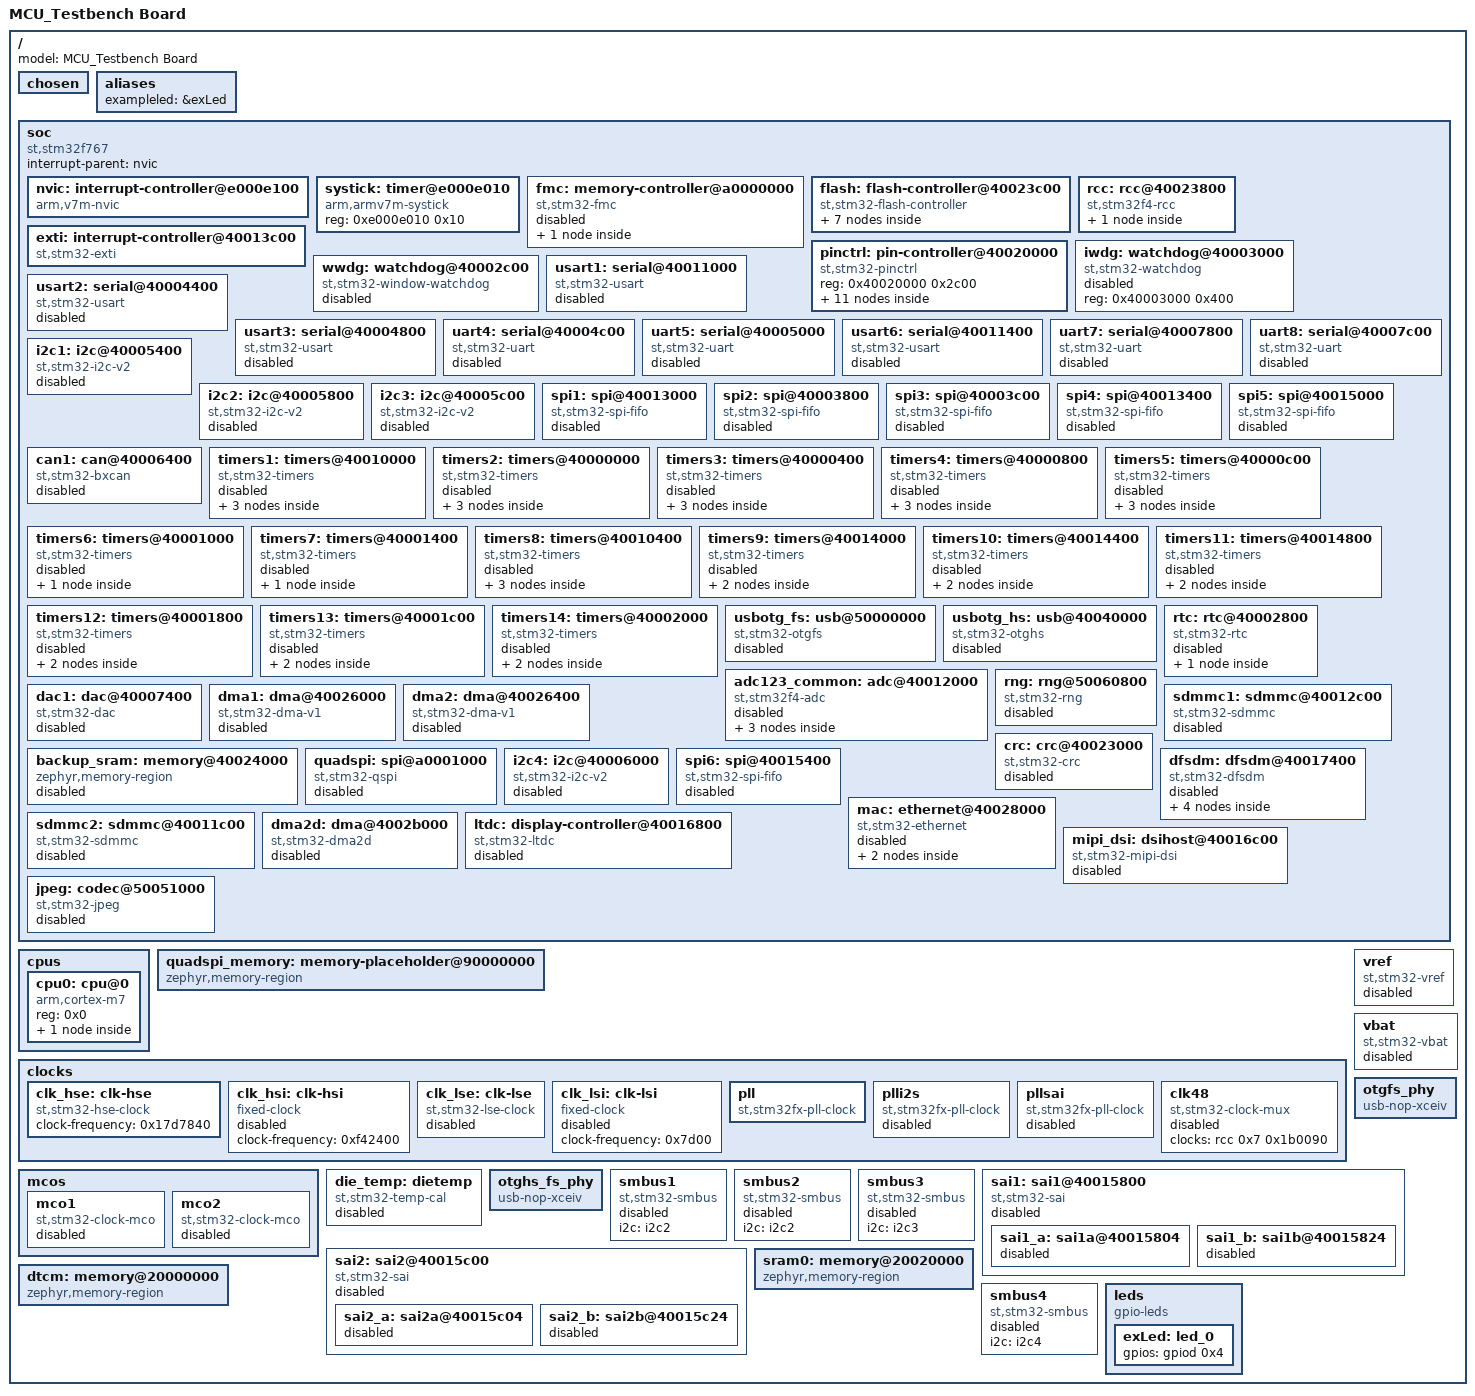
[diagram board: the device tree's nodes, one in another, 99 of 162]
/dts-v1/;

/* node '/' defined in zephyr\dts\common\skeleton.dtsi:9 */
/ {
	#address-cells = < 0x1 >;      /* in zephyr\dts\common\skeleton.dtsi:10 */
	#size-cells = < 0x1 >;         /* in zephyr\dts\common\skeleton.dtsi:11 */
	model = "MCU_Testbench Board"; /* in MCU_Testbench\boards\arm\MCU_Testbench\MCU_Testbench.dts:6 */

	/* node '/chosen' defined in zephyr\dts\common\skeleton.dtsi:13 */
	chosen {
		zephyr,crc = &crc;                /* in zephyr\dts\arm\st\f7\stm32f7.dtsi:28 */
		zephyr,entropy = &rng;            /* in zephyr\dts\arm\st\f7\stm32f7.dtsi:29 */
		zephyr,flash-controller = &flash; /* in zephyr\dts\arm\st\f7\stm32f7.dtsi:30 */
		zephyr,sram = &sram0;             /* in MCU_Testbench\boards\arm\MCU_Testbench\MCU_Testbench.dts:9 */
		zephyr,flash = &flash0;           /* in MCU_Testbench\boards\arm\MCU_Testbench\MCU_Testbench.dts:10 */
	};

	/* node '/aliases' defined in zephyr\dts\common\skeleton.dtsi:15 */
	aliases {
		exampleled = &exLed; /* in MCU_Testbench\boards\arm\MCU_Testbench\MCU_Testbench.dts:14 */
	};

	/* node '/soc' defined in zephyr\dts\arm\armv7-m.dtsi:6 */
	soc {
		#address-cells = < 0x1 >;     /* in zephyr\dts\arm\armv7-m.dtsi:7 */
		#size-cells = < 0x1 >;        /* in zephyr\dts\arm\armv7-m.dtsi:8 */
		interrupt-parent = < &nvic >; /* in zephyr\dts\arm\armv7-m.dtsi:10 */
		ranges;                       /* in zephyr\dts\arm\armv7-m.dtsi:11 */
		compatible = "st,stm32f767",
		             "st,stm32f7",
		             "simple-bus";    /* in zephyr\dts\arm\st\f7\stm32f767.dtsi:13 */

		/* node '/soc/interrupt-controller@e000e100' defined in zephyr\dts\arm\armv7-m.dtsi:13 */
		nvic: interrupt-controller@e000e100 {
			#address-cells = < 0x1 >;            /* in zephyr\dts\arm\armv7-m.dtsi:14 */
			compatible = "arm,v7m-nvic";         /* in zephyr\dts\arm\armv7-m.dtsi:15 */
			reg = < 0xe000e100 0xc00 >;          /* in zephyr\dts\arm\armv7-m.dtsi:16 */
			interrupt-controller;                /* in zephyr\dts\arm\armv7-m.dtsi:17 */
			#interrupt-cells = < 0x2 >;          /* in zephyr\dts\arm\armv7-m.dtsi:18 */
			arm,num-irq-priority-bits = < 0x4 >; /* in zephyr\dts\arm\st\f7\stm32f7.dtsi:1123 */
			phandle = < 0x1 >;                   /* in zephyr\dts\arm\armv7-m.dtsi:10 */
		};

		/* node '/soc/timer@e000e010' defined in zephyr\dts\arm\armv7-m.dtsi:21 */
		systick: timer@e000e010 {
			compatible = "arm,armv7m-systick"; /* in zephyr\dts\arm\armv7-m.dtsi:22 */
			reg = < 0xe000e010 0x10 >;         /* in zephyr\dts\arm\armv7-m.dtsi:23 */
		};

		/* node '/soc/memory-controller@a0000000' defined in zephyr\dts\arm\st\f7\stm32f7.dtsi:128 */
		fmc: memory-controller@a0000000 {
			compatible = "st,stm32-fmc"; /* in zephyr\dts\arm\st\f7\stm32f7.dtsi:129 */
			reg = < 0xa0000000 0x400 >;  /* in zephyr\dts\arm\st\f7\stm32f7.dtsi:130 */
			clocks = < &rcc 0x38 0x1 >;  /* in zephyr\dts\arm\st\f7\stm32f7.dtsi:131 */
			status = "disabled";         /* in zephyr\dts\arm\st\f7\stm32f7.dtsi:132 */

			/* node '/soc/memory-controller@a0000000/sdram' defined in zephyr\dts\arm\st\f7\stm32f7.dtsi:134 */
			sdram: sdram {
				compatible = "st,stm32-fmc-sdram"; /* in zephyr\dts\arm\st\f7\stm32f7.dtsi:135 */
				#address-cells = < 0x1 >;          /* in zephyr\dts\arm\st\f7\stm32f7.dtsi:136 */
				#size-cells = < 0x0 >;             /* in zephyr\dts\arm\st\f7\stm32f7.dtsi:137 */
				status = "disabled";               /* in zephyr\dts\arm\st\f7\stm32f7.dtsi:138 */
			};
		};

		/* node '/soc/flash-controller@40023c00' defined in zephyr\dts\arm\st\f7\stm32f7.dtsi:142 */
		flash: flash-controller@40023c00 {
			compatible = "st,stm32-flash-controller",
			             "st,stm32f7-flash-controller"; /* in zephyr\dts\arm\st\f7\stm32f7.dtsi:143 */
			reg = < 0x40023c00 0x400 >;                 /* in zephyr\dts\arm\st\f7\stm32f7.dtsi:144 */
			interrupts = < 0x4 0x0 >;                   /* in zephyr\dts\arm\st\f7\stm32f7.dtsi:145 */
			#address-cells = < 0x1 >;                   /* in zephyr\dts\arm\st\f7\stm32f7.dtsi:147 */
			#size-cells = < 0x1 >;                      /* in zephyr\dts\arm\st\f7\stm32f7.dtsi:148 */
			ranges;                                     /* in zephyr\dts\arm\st\f7\stm32f7.dtsi:149 */

			/* node '/soc/flash-controller@40023c00/flash@8000000' defined in zephyr\dts\arm\st\f7\stm32f7.dtsi:151 */
			flash0: flash@8000000 {
				compatible = "st,stm32-nv-flash",
				             "soc-nv-flash";      /* in zephyr\dts\arm\st\f7\stm32f7.dtsi:152 */
				#address-cells = < 0x1 >;         /* in zephyr\dts\arm\st\f7\stm32f7.dtsi:153 */
				#size-cells = < 0x1 >;            /* in zephyr\dts\arm\st\f7\stm32f7.dtsi:154 */
				write-block-size = < 0x1 >;       /* in zephyr\dts\arm\st\f7\stm32f7.dtsi:155 */
				max-erase-time = < 0xfa0 >;       /* in zephyr\dts\arm\st\f7\stm32f7.dtsi:157 */
				reg = < 0x8000000 0x200000 >;     /* in MCU_Testbench\boards\arm\MCU_Testbench\MCU_Testbench.dts:73 */
			};

			/* node '/soc/flash-controller@40023c00/flash@1ff0f000' defined in zephyr\dts\arm\st\f7\stm32f7.dtsi:160 */
			st_nvm_user_otp: flash@1ff0f000 {
				compatible = "st,stm32-nvm-otp"; /* in zephyr\dts\arm\st\f7\stm32f7.dtsi:161 */
				reg = < 0x1ff0f000 0x400 >;      /* in zephyr\dts\arm\st\f7\stm32f7.dtsi:162 */
				status = "disabled";             /* in zephyr\dts\arm\st\f7\stm32f7.dtsi:163 */
			};

			/* node '/soc/flash-controller@40023c00/flash@1ff0f400' defined in zephyr\dts\arm\st\f7\stm32f7.dtsi:177 */
			flash@1ff0f400 {
				compatible = "st,stm32-nvm-otp"; /* in zephyr\dts\arm\st\f7\stm32f7.dtsi:178 */
				reg = < 0x1ff0f400 0x100 >;      /* in zephyr\dts\arm\st\f7\stm32f7.dtsi:179 */

				/* node '/soc/flash-controller@40023c00/flash@1ff0f400/nvmem-layout' defined in zephyr\dts\arm\st\f7\stm32f7.dtsi:181 */
				nvmem-layout {
					compatible = "fixed-layout"; /* in zephyr\dts\arm\st\f7\stm32f7.dtsi:182 */
					#address-cells = < 0x1 >;    /* in zephyr\dts\arm\st\f7\stm32f7.dtsi:183 */
					#size-cells = < 0x1 >;       /* in zephyr\dts\arm\st\f7\stm32f7.dtsi:184 */

					/* node '/soc/flash-controller@40023c00/flash@1ff0f400/nvmem-layout/vrefint@4a' defined in zephyr\dts\arm\st\f7\stm32f7.dtsi:186 */
					vrefint_otp: vrefint@4a {
						reg = < 0x4a 0x2 >;          /* in zephyr\dts\arm\st\f7\stm32f7.dtsi:187 */
						#nvmem-cell-cells = < 0x0 >; /* in zephyr\dts\arm\st\f7\stm32f7.dtsi:188 */
						read-only;                   /* in zephyr\dts\arm\st\f7\stm32f7.dtsi:189 */
						phandle = < 0xb >;           /* in zephyr\dts\arm\st\f7\stm32f7.dtsi:1020 */
					};

					/* node '/soc/flash-controller@40023c00/flash@1ff0f400/nvmem-layout/ts-cal1@4c' defined in zephyr\dts\arm\st\f7\stm32f7.dtsi:192 */
					ts_cal1_otp: ts-cal1@4c {
						reg = < 0x4c 0x2 >;          /* in zephyr\dts\arm\st\f7\stm32f7.dtsi:193 */
						#nvmem-cell-cells = < 0x0 >; /* in zephyr\dts\arm\st\f7\stm32f7.dtsi:194 */
						read-only;                   /* in zephyr\dts\arm\st\f7\stm32f7.dtsi:195 */
						phandle = < 0x8 >;           /* in zephyr\dts\arm\st\f7\stm32f7.dtsi:1009 */
					};

					/* node '/soc/flash-controller@40023c00/flash@1ff0f400/nvmem-layout/ts-cal2@4e' defined in zephyr\dts\arm\st\f7\stm32f7.dtsi:198 */
					ts_cal2_otp: ts-cal2@4e {
						reg = < 0x4e 0x2 >;          /* in zephyr\dts\arm\st\f7\stm32f7.dtsi:199 */
						#nvmem-cell-cells = < 0x0 >; /* in zephyr\dts\arm\st\f7\stm32f7.dtsi:200 */
						read-only;                   /* in zephyr\dts\arm\st\f7\stm32f7.dtsi:201 */
						phandle = < 0x9 >;           /* in zephyr\dts\arm\st\f7\stm32f7.dtsi:1009 */
					};
				};
			};
		};

		/* node '/soc/rcc@40023800' defined in zephyr\dts\arm\st\f7\stm32f7.dtsi:207 */
		rcc: rcc@40023800 {
			compatible = "st,stm32f4-rcc";   /* in zephyr\dts\arm\st\f7\stm32f7.dtsi:208 */
			#clock-cells = < 0x2 >;          /* in zephyr\dts\arm\st\f7\stm32f7.dtsi:209 */
			reg = < 0x40023800 0x400 >;      /* in zephyr\dts\arm\st\f7\stm32f7.dtsi:210 */
			clocks = < &pll >;               /* in MCU_Testbench\boards\arm\MCU_Testbench\MCU_Testbench.dts:58 */
			clock-frequency = < 0xcdfe600 >; /* in MCU_Testbench\boards\arm\MCU_Testbench\MCU_Testbench.dts:59 */
			ahb-prescaler = < 0x1 >;         /* in MCU_Testbench\boards\arm\MCU_Testbench\MCU_Testbench.dts:60 */
			apb1-prescaler = < 0x4 >;        /* in MCU_Testbench\boards\arm\MCU_Testbench\MCU_Testbench.dts:61 */
			apb2-prescaler = < 0x2 >;        /* in MCU_Testbench\boards\arm\MCU_Testbench\MCU_Testbench.dts:62 */
			phandle = < 0x2 >;               /* in zephyr\dts\arm\st\f7\stm32f7.dtsi:131 */

			/* node '/soc/rcc@40023800/reset-controller' defined in zephyr\dts\arm\st\f7\stm32f7.dtsi:212 */
			rctl: reset-controller {
				compatible = "st,stm32-rcc-rctl"; /* in zephyr\dts\arm\st\f7\stm32f7.dtsi:213 */
				#reset-cells = < 0x1 >;           /* in zephyr\dts\arm\st\f7\stm32f7.dtsi:214 */
				phandle = < 0x4 >;                /* in zephyr\dts\arm\st\f7\stm32f7.dtsi:332 */
			};
		};

		/* node '/soc/interrupt-controller@40013c00' defined in zephyr\dts\arm\st\f7\stm32f7.dtsi:218 */
		exti: interrupt-controller@40013c00 {
			compatible = "st,stm32-exti";  /* in zephyr\dts\arm\st\f7\stm32f7.dtsi:219 */
			interrupt-controller;          /* in zephyr\dts\arm\st\f7\stm32f7.dtsi:220 */
			#interrupt-cells = < 0x1 >;    /* in zephyr\dts\arm\st\f7\stm32f7.dtsi:221 */
			#address-cells = < 0x0 >;      /* in zephyr\dts\arm\st\f7\stm32f7.dtsi:222 */
			reg = < 0x40013c00 0x400 >;    /* in zephyr\dts\arm\st\f7\stm32f7.dtsi:223 */
			clocks = < &rcc 0x44 0x4000 >; /* in zephyr\dts\arm\st\f7\stm32f7.dtsi:224 */
			num-lines = < 0x20 >;          /* in zephyr\dts\arm\st\f7\stm32f7.dtsi:225 */
			interrupts = < 0x6 0x0 >,
			             < 0x7 0x0 >,
			             < 0x8 0x0 >,
			             < 0x9 0x0 >,
			             < 0xa 0x0 >,
			             < 0x17 0x0 >,
			             < 0x28 0x0 >;     /* in zephyr\dts\arm\st\f7\stm32f7.dtsi:226 */
			interrupt-names = "line0",
			                  "line1",
			                  "line2",
			                  "line3",
			                  "line4",
			                  "line5-9",
			                  "line10-15"; /* in zephyr\dts\arm\st\f7\stm32f7.dtsi:228 */
			line-ranges = < 0x0 0x1 >,
			              < 0x1 0x1 >,
			              < 0x2 0x1 >,
			              < 0x3 0x1 >,
			              < 0x4 0x1 >,
			              < 0x5 0x5 >,
			              < 0xa 0x6 >;     /* in zephyr\dts\arm\st\f7\stm32f7.dtsi:230 */
		};

		/* node '/soc/pin-controller@40020000' defined in zephyr\dts\arm\st\f7\stm32f7.dtsi:234 */
		pinctrl: pin-controller@40020000 {
			compatible = "st,stm32-pinctrl"; /* in zephyr\dts\arm\st\f7\stm32f7.dtsi:235 */
			#address-cells = < 0x1 >;        /* in zephyr\dts\arm\st\f7\stm32f7.dtsi:236 */
			#size-cells = < 0x1 >;           /* in zephyr\dts\arm\st\f7\stm32f7.dtsi:237 */
			ranges;                          /* in zephyr\dts\arm\st\f7\stm32f7.dtsi:239 */
			reg = < 0x40020000 0x2c00 >;     /* in zephyr\dts\arm\st\f7\stm32f765.dtsi:30 */

			/* node '/soc/pin-controller@40020000/gpio@40020000' defined in zephyr\dts\arm\st\f7\stm32f7.dtsi:241 */
			gpioa: gpio@40020000 {
				compatible = "st,stm32-gpio"; /* in zephyr\dts\arm\st\f7\stm32f7.dtsi:242 */
				gpio-controller;              /* in zephyr\dts\arm\st\f7\stm32f7.dtsi:243 */
				#gpio-cells = < 0x2 >;        /* in zephyr\dts\arm\st\f7\stm32f7.dtsi:244 */
				reg = < 0x40020000 0x400 >;   /* in zephyr\dts\arm\st\f7\stm32f7.dtsi:245 */
				clocks = < &rcc 0x30 0x1 >;   /* in zephyr\dts\arm\st\f7\stm32f7.dtsi:246 */
			};

			/* node '/soc/pin-controller@40020000/gpio@40020400' defined in zephyr\dts\arm\st\f7\stm32f7.dtsi:249 */
			gpiob: gpio@40020400 {
				compatible = "st,stm32-gpio"; /* in zephyr\dts\arm\st\f7\stm32f7.dtsi:250 */
				gpio-controller;              /* in zephyr\dts\arm\st\f7\stm32f7.dtsi:251 */
				#gpio-cells = < 0x2 >;        /* in zephyr\dts\arm\st\f7\stm32f7.dtsi:252 */
				reg = < 0x40020400 0x400 >;   /* in zephyr\dts\arm\st\f7\stm32f7.dtsi:253 */
				clocks = < &rcc 0x30 0x2 >;   /* in zephyr\dts\arm\st\f7\stm32f7.dtsi:254 */
			};

			/* node '/soc/pin-controller@40020000/gpio@40020800' defined in zephyr\dts\arm\st\f7\stm32f7.dtsi:257 */
			gpioc: gpio@40020800 {
				compatible = "st,stm32-gpio"; /* in zephyr\dts\arm\st\f7\stm32f7.dtsi:258 */
				gpio-controller;              /* in zephyr\dts\arm\st\f7\stm32f7.dtsi:259 */
				#gpio-cells = < 0x2 >;        /* in zephyr\dts\arm\st\f7\stm32f7.dtsi:260 */
				reg = < 0x40020800 0x400 >;   /* in zephyr\dts\arm\st\f7\stm32f7.dtsi:261 */
				clocks = < &rcc 0x30 0x4 >;   /* in zephyr\dts\arm\st\f7\stm32f7.dtsi:262 */
			};

			/* node '/soc/pin-controller@40020000/gpio@40020c00' defined in zephyr\dts\arm\st\f7\stm32f7.dtsi:265 */
			gpiod: gpio@40020c00 {
				compatible = "st,stm32-gpio"; /* in zephyr\dts\arm\st\f7\stm32f7.dtsi:266 */
				gpio-controller;              /* in zephyr\dts\arm\st\f7\stm32f7.dtsi:267 */
				#gpio-cells = < 0x2 >;        /* in zephyr\dts\arm\st\f7\stm32f7.dtsi:268 */
				reg = < 0x40020c00 0x400 >;   /* in zephyr\dts\arm\st\f7\stm32f7.dtsi:269 */
				clocks = < &rcc 0x30 0x8 >;   /* in zephyr\dts\arm\st\f7\stm32f7.dtsi:270 */
				phandle = < 0x10 >;           /* in MCU_Testbench\boards\arm\MCU_Testbench\MCU_Testbench.dts:20 */
			};

			/* node '/soc/pin-controller@40020000/gpio@40021000' defined in zephyr\dts\arm\st\f7\stm32f7.dtsi:273 */
			gpioe: gpio@40021000 {
				compatible = "st,stm32-gpio"; /* in zephyr\dts\arm\st\f7\stm32f7.dtsi:274 */
				gpio-controller;              /* in zephyr\dts\arm\st\f7\stm32f7.dtsi:275 */
				#gpio-cells = < 0x2 >;        /* in zephyr\dts\arm\st\f7\stm32f7.dtsi:276 */
				reg = < 0x40021000 0x400 >;   /* in zephyr\dts\arm\st\f7\stm32f7.dtsi:277 */
				clocks = < &rcc 0x30 0x10 >;  /* in zephyr\dts\arm\st\f7\stm32f7.dtsi:278 */
			};

			/* node '/soc/pin-controller@40020000/gpio@40021400' defined in zephyr\dts\arm\st\f7\stm32f7.dtsi:281 */
			gpiof: gpio@40021400 {
				compatible = "st,stm32-gpio"; /* in zephyr\dts\arm\st\f7\stm32f7.dtsi:282 */
				gpio-controller;              /* in zephyr\dts\arm\st\f7\stm32f7.dtsi:283 */
				#gpio-cells = < 0x2 >;        /* in zephyr\dts\arm\st\f7\stm32f7.dtsi:284 */
				reg = < 0x40021400 0x400 >;   /* in zephyr\dts\arm\st\f7\stm32f7.dtsi:285 */
				clocks = < &rcc 0x30 0x20 >;  /* in zephyr\dts\arm\st\f7\stm32f7.dtsi:286 */
			};

			/* node '/soc/pin-controller@40020000/gpio@40021800' defined in zephyr\dts\arm\st\f7\stm32f7.dtsi:289 */
			gpiog: gpio@40021800 {
				compatible = "st,stm32-gpio"; /* in zephyr\dts\arm\st\f7\stm32f7.dtsi:290 */
				gpio-controller;              /* in zephyr\dts\arm\st\f7\stm32f7.dtsi:291 */
				#gpio-cells = < 0x2 >;        /* in zephyr\dts\arm\st\f7\stm32f7.dtsi:292 */
				reg = < 0x40021800 0x400 >;   /* in zephyr\dts\arm\st\f7\stm32f7.dtsi:293 */
				clocks = < &rcc 0x30 0x40 >;  /* in zephyr\dts\arm\st\f7\stm32f7.dtsi:294 */
			};

			/* node '/soc/pin-controller@40020000/gpio@40021c00' defined in zephyr\dts\arm\st\f7\stm32f7.dtsi:297 */
			gpioh: gpio@40021c00 {
				compatible = "st,stm32-gpio"; /* in zephyr\dts\arm\st\f7\stm32f7.dtsi:298 */
				gpio-controller;              /* in zephyr\dts\arm\st\f7\stm32f7.dtsi:299 */
				#gpio-cells = < 0x2 >;        /* in zephyr\dts\arm\st\f7\stm32f7.dtsi:300 */
				reg = < 0x40021c00 0x400 >;   /* in zephyr\dts\arm\st\f7\stm32f7.dtsi:301 */
				clocks = < &rcc 0x30 0x80 >;  /* in zephyr\dts\arm\st\f7\stm32f7.dtsi:302 */
			};

			/* node '/soc/pin-controller@40020000/gpio@40022000' defined in zephyr\dts\arm\st\f7\stm32f7.dtsi:305 */
			gpioi: gpio@40022000 {
				compatible = "st,stm32-gpio"; /* in zephyr\dts\arm\st\f7\stm32f7.dtsi:306 */
				gpio-controller;              /* in zephyr\dts\arm\st\f7\stm32f7.dtsi:307 */
				#gpio-cells = < 0x2 >;        /* in zephyr\dts\arm\st\f7\stm32f7.dtsi:308 */
				reg = < 0x40022000 0x400 >;   /* in zephyr\dts\arm\st\f7\stm32f7.dtsi:309 */
				clocks = < &rcc 0x30 0x100 >; /* in zephyr\dts\arm\st\f7\stm32f7.dtsi:310 */
			};

			/* node '/soc/pin-controller@40020000/gpio@40022400' defined in zephyr\dts\arm\st\f7\stm32f765.dtsi:32 */
			gpioj: gpio@40022400 {
				compatible = "st,stm32-gpio"; /* in zephyr\dts\arm\st\f7\stm32f765.dtsi:33 */
				gpio-controller;              /* in zephyr\dts\arm\st\f7\stm32f765.dtsi:34 */
				#gpio-cells = < 0x2 >;        /* in zephyr\dts\arm\st\f7\stm32f765.dtsi:35 */
				reg = < 0x40022400 0x400 >;   /* in zephyr\dts\arm\st\f7\stm32f765.dtsi:36 */
				clocks = < &rcc 0x30 0x200 >; /* in zephyr\dts\arm\st\f7\stm32f765.dtsi:37 */
			};

			/* node '/soc/pin-controller@40020000/gpio@40022800' defined in zephyr\dts\arm\st\f7\stm32f765.dtsi:40 */
			gpiok: gpio@40022800 {
				compatible = "st,stm32-gpio"; /* in zephyr\dts\arm\st\f7\stm32f765.dtsi:41 */
				gpio-controller;              /* in zephyr\dts\arm\st\f7\stm32f765.dtsi:42 */
				#gpio-cells = < 0x2 >;        /* in zephyr\dts\arm\st\f7\stm32f765.dtsi:43 */
				reg = < 0x40022800 0x400 >;   /* in zephyr\dts\arm\st\f7\stm32f765.dtsi:44 */
				clocks = < &rcc 0x30 0x400 >; /* in zephyr\dts\arm\st\f7\stm32f765.dtsi:45 */
			};
		};

		/* node '/soc/watchdog@40003000' defined in zephyr\dts\arm\st\f7\stm32f7.dtsi:314 */
		iwdg: watchdog@40003000 {
			compatible = "st,stm32-watchdog"; /* in zephyr\dts\arm\st\f7\stm32f7.dtsi:315 */
			reg = < 0x40003000 0x400 >;       /* in zephyr\dts\arm\st\f7\stm32f7.dtsi:316 */
			status = "disabled";              /* in zephyr\dts\arm\st\f7\stm32f7.dtsi:317 */
		};

		/* node '/soc/watchdog@40002c00' defined in zephyr\dts\arm\st\f7\stm32f7.dtsi:320 */
		wwdg: watchdog@40002c00 {
			compatible = "st,stm32-window-watchdog"; /* in zephyr\dts\arm\st\f7\stm32f7.dtsi:321 */
			reg = < 0x40002c00 0x400 >;              /* in zephyr\dts\arm\st\f7\stm32f7.dtsi:322 */
			clocks = < &rcc 0x40 0x800 >;            /* in zephyr\dts\arm\st\f7\stm32f7.dtsi:323 */
			interrupts = < 0x0 0x0 >;                /* in zephyr\dts\arm\st\f7\stm32f7.dtsi:324 */
			status = "disabled";                     /* in zephyr\dts\arm\st\f7\stm32f7.dtsi:325 */
		};

		/* node '/soc/serial@40011000' defined in zephyr\dts\arm\st\f7\stm32f7.dtsi:328 */
		usart1: serial@40011000 {
			compatible = "st,stm32-usart",
			             "st,stm32-uart";  /* in zephyr\dts\arm\st\f7\stm32f7.dtsi:329 */
			reg = < 0x40011000 0x400 >;    /* in zephyr\dts\arm\st\f7\stm32f7.dtsi:330 */
			clocks = < &rcc 0x44 0x10 >;   /* in zephyr\dts\arm\st\f7\stm32f7.dtsi:331 */
			resets = < &rctl 0x484 >;      /* in zephyr\dts\arm\st\f7\stm32f7.dtsi:332 */
			interrupts = < 0x25 0x0 >;     /* in zephyr\dts\arm\st\f7\stm32f7.dtsi:333 */
			status = "disabled";           /* in zephyr\dts\arm\st\f7\stm32f7.dtsi:334 */
		};

		/* node '/soc/serial@40004400' defined in zephyr\dts\arm\st\f7\stm32f7.dtsi:337 */
		usart2: serial@40004400 {
			compatible = "st,stm32-usart",
			             "st,stm32-uart";   /* in zephyr\dts\arm\st\f7\stm32f7.dtsi:338 */
			reg = < 0x40004400 0x400 >;     /* in zephyr\dts\arm\st\f7\stm32f7.dtsi:339 */
			clocks = < &rcc 0x40 0x20000 >; /* in zephyr\dts\arm\st\f7\stm32f7.dtsi:340 */
			resets = < &rctl 0x411 >;       /* in zephyr\dts\arm\st\f7\stm32f7.dtsi:341 */
			interrupts = < 0x26 0x0 >;      /* in zephyr\dts\arm\st\f7\stm32f7.dtsi:342 */
			status = "disabled";            /* in zephyr\dts\arm\st\f7\stm32f7.dtsi:343 */
		};

		/* node '/soc/serial@40004800' defined in zephyr\dts\arm\st\f7\stm32f7.dtsi:346 */
		usart3: serial@40004800 {
			compatible = "st,stm32-usart",
			             "st,stm32-uart";   /* in zephyr\dts\arm\st\f7\stm32f7.dtsi:347 */
			reg = < 0x40004800 0x400 >;     /* in zephyr\dts\arm\st\f7\stm32f7.dtsi:348 */
			clocks = < &rcc 0x40 0x40000 >; /* in zephyr\dts\arm\st\f7\stm32f7.dtsi:349 */
			resets = < &rctl 0x412 >;       /* in zephyr\dts\arm\st\f7\stm32f7.dtsi:350 */
			interrupts = < 0x27 0x0 >;      /* in zephyr\dts\arm\st\f7\stm32f7.dtsi:351 */
			status = "disabled";            /* in zephyr\dts\arm\st\f7\stm32f7.dtsi:352 */
		};

		/* node '/soc/serial@40004c00' defined in zephyr\dts\arm\st\f7\stm32f7.dtsi:355 */
		uart4: serial@40004c00 {
			compatible = "st,stm32-uart";   /* in zephyr\dts\arm\st\f7\stm32f7.dtsi:356 */
			reg = < 0x40004c00 0x400 >;     /* in zephyr\dts\arm\st\f7\stm32f7.dtsi:357 */
			clocks = < &rcc 0x40 0x80000 >; /* in zephyr\dts\arm\st\f7\stm32f7.dtsi:358 */
			resets = < &rctl 0x413 >;       /* in zephyr\dts\arm\st\f7\stm32f7.dtsi:359 */
			interrupts = < 0x34 0x0 >;      /* in zephyr\dts\arm\st\f7\stm32f7.dtsi:360 */
			status = "disabled";            /* in zephyr\dts\arm\st\f7\stm32f7.dtsi:361 */
		};

		/* node '/soc/serial@40005000' defined in zephyr\dts\arm\st\f7\stm32f7.dtsi:364 */
		uart5: serial@40005000 {
			compatible = "st,stm32-uart";    /* in zephyr\dts\arm\st\f7\stm32f7.dtsi:365 */
			reg = < 0x40005000 0x400 >;      /* in zephyr\dts\arm\st\f7\stm32f7.dtsi:366 */
			clocks = < &rcc 0x40 0x100000 >; /* in zephyr\dts\arm\st\f7\stm32f7.dtsi:367 */
			resets = < &rctl 0x414 >;        /* in zephyr\dts\arm\st\f7\stm32f7.dtsi:368 */
			interrupts = < 0x35 0x0 >;       /* in zephyr\dts\arm\st\f7\stm32f7.dtsi:369 */
			status = "disabled";             /* in zephyr\dts\arm\st\f7\stm32f7.dtsi:370 */
		};

		/* node '/soc/serial@40011400' defined in zephyr\dts\arm\st\f7\stm32f7.dtsi:373 */
		usart6: serial@40011400 {
			compatible = "st,stm32-usart",
			             "st,stm32-uart";  /* in zephyr\dts\arm\st\f7\stm32f7.dtsi:374 */
			reg = < 0x40011400 0x400 >;    /* in zephyr\dts\arm\st\f7\stm32f7.dtsi:375 */
			clocks = < &rcc 0x44 0x20 >;   /* in zephyr\dts\arm\st\f7\stm32f7.dtsi:376 */
			resets = < &rctl 0x485 >;      /* in zephyr\dts\arm\st\f7\stm32f7.dtsi:377 */
			interrupts = < 0x47 0x0 >;     /* in zephyr\dts\arm\st\f7\stm32f7.dtsi:378 */
			status = "disabled";           /* in zephyr\dts\arm\st\f7\stm32f7.dtsi:379 */
		};

		/* node '/soc/serial@40007800' defined in zephyr\dts\arm\st\f7\stm32f7.dtsi:382 */
		uart7: serial@40007800 {
			compatible = "st,stm32-uart";      /* in zephyr\dts\arm\st\f7\stm32f7.dtsi:383 */
			reg = < 0x40007800 0x400 >;        /* in zephyr\dts\arm\st\f7\stm32f7.dtsi:384 */
			clocks = < &rcc 0x40 0x40000000 >; /* in zephyr\dts\arm\st\f7\stm32f7.dtsi:385 */
			resets = < &rctl 0x41e >;          /* in zephyr\dts\arm\st\f7\stm32f7.dtsi:386 */
			interrupts = < 0x52 0x0 >;         /* in zephyr\dts\arm\st\f7\stm32f7.dtsi:387 */
			status = "disabled";               /* in zephyr\dts\arm\st\f7\stm32f7.dtsi:388 */
		};

		/* node '/soc/serial@40007c00' defined in zephyr\dts\arm\st\f7\stm32f7.dtsi:391 */
		uart8: serial@40007c00 {
			compatible = "st,stm32-uart";      /* in zephyr\dts\arm\st\f7\stm32f7.dtsi:392 */
			reg = < 0x40007c00 0x400 >;        /* in zephyr\dts\arm\st\f7\stm32f7.dtsi:393 */
			clocks = < &rcc 0x40 0x80000000 >; /* in zephyr\dts\arm\st\f7\stm32f7.dtsi:394 */
			resets = < &rctl 0x41f >;          /* in zephyr\dts\arm\st\f7\stm32f7.dtsi:395 */
			interrupts = < 0x53 0x0 >;         /* in zephyr\dts\arm\st\f7\stm32f7.dtsi:396 */
			status = "disabled";               /* in zephyr\dts\arm\st\f7\stm32f7.dtsi:397 */
		};

		/* node '/soc/i2c@40005400' defined in zephyr\dts\arm\st\f7\stm32f7.dtsi:400 */
		i2c1: i2c@40005400 {
			compatible = "st,stm32-i2c-v2";  /* in zephyr\dts\arm\st\f7\stm32f7.dtsi:401 */
			clock-frequency = < 0x186a0 >;   /* in zephyr\dts\arm\st\f7\stm32f7.dtsi:402 */
			#address-cells = < 0x1 >;        /* in zephyr\dts\arm\st\f7\stm32f7.dtsi:403 */
			#size-cells = < 0x0 >;           /* in zephyr\dts\arm\st\f7\stm32f7.dtsi:404 */
			reg = < 0x40005400 0x400 >;      /* in zephyr\dts\arm\st\f7\stm32f7.dtsi:405 */
			clocks = < &rcc 0x40 0x200000 >; /* in zephyr\dts\arm\st\f7\stm32f7.dtsi:406 */
			interrupts = < 0x1f 0x0 >,
			             < 0x20 0x0 >;       /* in zephyr\dts\arm\st\f7\stm32f7.dtsi:407 */
			interrupt-names = "event",
			                  "error";       /* in zephyr\dts\arm\st\f7\stm32f7.dtsi:408 */
			status = "disabled";             /* in zephyr\dts\arm\st\f7\stm32f7.dtsi:409 */
		};

		/* node '/soc/i2c@40005800' defined in zephyr\dts\arm\st\f7\stm32f7.dtsi:412 */
		i2c2: i2c@40005800 {
			compatible = "st,stm32-i2c-v2";  /* in zephyr\dts\arm\st\f7\stm32f7.dtsi:413 */
			clock-frequency = < 0x186a0 >;   /* in zephyr\dts\arm\st\f7\stm32f7.dtsi:414 */
			#address-cells = < 0x1 >;        /* in zephyr\dts\arm\st\f7\stm32f7.dtsi:415 */
			#size-cells = < 0x0 >;           /* in zephyr\dts\arm\st\f7\stm32f7.dtsi:416 */
			reg = < 0x40005800 0x400 >;      /* in zephyr\dts\arm\st\f7\stm32f7.dtsi:417 */
			clocks = < &rcc 0x40 0x400000 >; /* in zephyr\dts\arm\st\f7\stm32f7.dtsi:418 */
			interrupts = < 0x21 0x0 >,
			             < 0x22 0x0 >;       /* in zephyr\dts\arm\st\f7\stm32f7.dtsi:419 */
			interrupt-names = "event",
			                  "error";       /* in zephyr\dts\arm\st\f7\stm32f7.dtsi:420 */
			status = "disabled";             /* in zephyr\dts\arm\st\f7\stm32f7.dtsi:421 */
			phandle = < 0xc >;               /* in zephyr\dts\arm\st\f7\stm32f7.dtsi:1047 */
		};

		/* node '/soc/i2c@40005c00' defined in zephyr\dts\arm\st\f7\stm32f7.dtsi:424 */
		i2c3: i2c@40005c00 {
			compatible = "st,stm32-i2c-v2";  /* in zephyr\dts\arm\st\f7\stm32f7.dtsi:425 */
			clock-frequency = < 0x186a0 >;   /* in zephyr\dts\arm\st\f7\stm32f7.dtsi:426 */
			#address-cells = < 0x1 >;        /* in zephyr\dts\arm\st\f7\stm32f7.dtsi:427 */
			#size-cells = < 0x0 >;           /* in zephyr\dts\arm\st\f7\stm32f7.dtsi:428 */
			reg = < 0x40005c00 0x400 >;      /* in zephyr\dts\arm\st\f7\stm32f7.dtsi:429 */
			clocks = < &rcc 0x40 0x800000 >; /* in zephyr\dts\arm\st\f7\stm32f7.dtsi:430 */
			interrupts = < 0x48 0x0 >,
			             < 0x49 0x0 >;       /* in zephyr\dts\arm\st\f7\stm32f7.dtsi:431 */
			interrupt-names = "event",
			                  "error";       /* in zephyr\dts\arm\st\f7\stm32f7.dtsi:432 */
			status = "disabled";             /* in zephyr\dts\arm\st\f7\stm32f7.dtsi:433 */
			phandle = < 0xd >;               /* in zephyr\dts\arm\st\f7\stm32f7.dtsi:1063 */
		};

		/* node '/soc/spi@40013000' defined in zephyr\dts\arm\st\f7\stm32f7.dtsi:436 */
		spi1: spi@40013000 {
			compatible = "st,stm32-spi-fifo",
			             "st,stm32-spi";            /* in zephyr\dts\arm\st\f7\stm32f7.dtsi:437 */
			#address-cells = < 0x1 >;               /* in zephyr\dts\arm\st\f7\stm32f7.dtsi:438 */
			#size-cells = < 0x0 >;                  /* in zephyr\dts\arm\st\f7\stm32f7.dtsi:439 */
			reg = < 0x40013000 0x400 >;             /* in zephyr\dts\arm\st\f7\stm32f7.dtsi:440 */
			clocks = < &rcc 0x44 0x1000 >;          /* in zephyr\dts\arm\st\f7\stm32f7.dtsi:441 */
			interrupts = < 0x23 0x0 >;              /* in zephyr\dts\arm\st\f7\stm32f7.dtsi:442 */
			st,spi-data-width = "full-4-to-16-bit"; /* in zephyr\dts\arm\st\f7\stm32f7.dtsi:443 */
			status = "disabled";                    /* in zephyr\dts\arm\st\f7\stm32f7.dtsi:444 */
		};

		/* node '/soc/spi@40003800' defined in zephyr\dts\arm\st\f7\stm32f7.dtsi:447 */
		spi2: spi@40003800 {
			compatible = "st,stm32-spi-fifo",
			             "st,stm32-spi";            /* in zephyr\dts\arm\st\f7\stm32f7.dtsi:448 */
			#address-cells = < 0x1 >;               /* in zephyr\dts\arm\st\f7\stm32f7.dtsi:449 */
			#size-cells = < 0x0 >;                  /* in zephyr\dts\arm\st\f7\stm32f7.dtsi:450 */
			reg = < 0x40003800 0x400 >;             /* in zephyr\dts\arm\st\f7\stm32f7.dtsi:451 */
			clocks = < &rcc 0x40 0x4000 >;          /* in zephyr\dts\arm\st\f7\stm32f7.dtsi:452 */
			interrupts = < 0x24 0x0 >;              /* in zephyr\dts\arm\st\f7\stm32f7.dtsi:453 */
			st,spi-data-width = "full-4-to-16-bit"; /* in zephyr\dts\arm\st\f7\stm32f7.dtsi:454 */
			status = "disabled";                    /* in zephyr\dts\arm\st\f7\stm32f7.dtsi:455 */
		};

		/* node '/soc/spi@40003c00' defined in zephyr\dts\arm\st\f7\stm32f7.dtsi:458 */
		spi3: spi@40003c00 {
			compatible = "st,stm32-spi-fifo",
			             "st,stm32-spi";            /* in zephyr\dts\arm\st\f7\stm32f7.dtsi:459 */
			#address-cells = < 0x1 >;               /* in zephyr\dts\arm\st\f7\stm32f7.dtsi:460 */
			#size-cells = < 0x0 >;                  /* in zephyr\dts\arm\st\f7\stm32f7.dtsi:461 */
			reg = < 0x40003c00 0x400 >;             /* in zephyr\dts\arm\st\f7\stm32f7.dtsi:462 */
			clocks = < &rcc 0x40 0x8000 >;          /* in zephyr\dts\arm\st\f7\stm32f7.dtsi:463 */
			interrupts = < 0x33 0x0 >;              /* in zephyr\dts\arm\st\f7\stm32f7.dtsi:464 */
			st,spi-data-width = "full-4-to-16-bit"; /* in zephyr\dts\arm\st\f7\stm32f7.dtsi:465 */
			status = "disabled";                    /* in zephyr\dts\arm\st\f7\stm32f7.dtsi:466 */
		};

		/* node '/soc/spi@40013400' defined in zephyr\dts\arm\st\f7\stm32f7.dtsi:469 */
		spi4: spi@40013400 {
			compatible = "st,stm32-spi-fifo",
			             "st,stm32-spi";            /* in zephyr\dts\arm\st\f7\stm32f7.dtsi:470 */
			#address-cells = < 0x1 >;               /* in zephyr\dts\arm\st\f7\stm32f7.dtsi:471 */
			#size-cells = < 0x0 >;                  /* in zephyr\dts\arm\st\f7\stm32f7.dtsi:472 */
			reg = < 0x40013400 0x400 >;             /* in zephyr\dts\arm\st\f7\stm32f7.dtsi:473 */
			clocks = < &rcc 0x44 0x2000 >;          /* in zephyr\dts\arm\st\f7\stm32f7.dtsi:474 */
			interrupts = < 0x54 0x0 >;              /* in zephyr\dts\arm\st\f7\stm32f7.dtsi:475 */
			st,spi-data-width = "full-4-to-16-bit"; /* in zephyr\dts\arm\st\f7\stm32f7.dtsi:476 */
			status = "disabled";                    /* in zephyr\dts\arm\st\f7\stm32f7.dtsi:477 */
		};

		/* node '/soc/spi@40015000' defined in zephyr\dts\arm\st\f7\stm32f7.dtsi:480 */
		spi5: spi@40015000 {
			compatible = "st,stm32-spi-fifo",
			             "st,stm32-spi";            /* in zephyr\dts\arm\st\f7\stm32f7.dtsi:481 */
			#address-cells = < 0x1 >;               /* in zephyr\dts\arm\st\f7\stm32f7.dtsi:482 */
			#size-cells = < 0x0 >;                  /* in zephyr\dts\arm\st\f7\stm32f7.dtsi:483 */
			reg = < 0x40015000 0x400 >;             /* in zephyr\dts\arm\st\f7\stm32f7.dtsi:484 */
			clocks = < &rcc 0x44 0x100000 >;        /* in zephyr\dts\arm\st\f7\stm32f7.dtsi:485 */
			interrupts = < 0x55 0x0 >;              /* in zephyr\dts\arm\st\f7\stm32f7.dtsi:486 */
			st,spi-data-width = "full-4-to-16-bit"; /* in zephyr\dts\arm\st\f7\stm32f7.dtsi:487 */
			status = "disabled";                    /* in zephyr\dts\arm\st\f7\stm32f7.dtsi:488 */
		};

		/* node '/soc/can@40006400' defined in zephyr\dts\arm\st\f7\stm32f7.dtsi:491 */
		can1: can@40006400 {
			compatible = "st,stm32-bxcan";    /* in zephyr\dts\arm\st\f7\stm32f7.dtsi:492 */
			reg = < 0x40006400 0x400 >;       /* in zephyr\dts\arm\st\f7\stm32f7.dtsi:493 */
			interrupts = < 0x13 0x0 >,
			             < 0x14 0x0 >,
			             < 0x15 0x0 >,
			             < 0x16 0x0 >;        /* in zephyr\dts\arm\st\f7\stm32f7.dtsi:494 */
			interrupt-names = "TX",
			                  "RX0",
			                  "RX1",
			                  "SCE";          /* in zephyr\dts\arm\st\f7\stm32f7.dtsi:495 */
			clocks = < &rcc 0x40 0x2000000 >; /* in zephyr\dts\arm\st\f7\stm32f7.dtsi:496 */
			status = "disabled";              /* in zephyr\dts\arm\st\f7\stm32f7.dtsi:497 */
		};

		/* node '/soc/timers@40010000' defined in zephyr\dts\arm\st\f7\stm32f7.dtsi:500 */
		timers1: timers@40010000 {
			compatible = "st,stm32-timers"; /* in zephyr\dts\arm\st\f7\stm32f7.dtsi:501 */
			reg = < 0x40010000 0x400 >;     /* in zephyr\dts\arm\st\f7\stm32f7.dtsi:502 */
			clocks = < &rcc 0x44 0x1 >,
			         < &rcc 0x14 0xff >;    /* in zephyr\dts\arm\st\f7\stm32f7.dtsi:503 */
			resets = < &rctl 0x480 >;       /* in zephyr\dts\arm\st\f7\stm32f7.dtsi:505 */
			interrupts = < 0x18 0x0 >,
			             < 0x19 0x0 >,
			             < 0x1a 0x0 >,
			             < 0x1b 0x0 >;      /* in zephyr\dts\arm\st\f7\stm32f7.dtsi:506 */
			interrupt-names = "brk",
			                  "up",
			                  "trgcom",
			                  "cc";         /* in zephyr\dts\arm\st\f7\stm32f7.dtsi:507 */
			st,prescaler = < 0x0 >;         /* in zephyr\dts\arm\st\f7\stm32f7.dtsi:508 */
			status = "disabled";            /* in zephyr\dts\arm\st\f7\stm32f7.dtsi:509 */

			/* node '/soc/timers@40010000/pwm' defined in zephyr\dts\arm\st\f7\stm32f7.dtsi:511 */
			pwm {
				compatible = "st,stm32-pwm"; /* in zephyr\dts\arm\st\f7\stm32f7.dtsi:512 */
				status = "disabled";         /* in zephyr\dts\arm\st\f7\stm32f7.dtsi:513 */
				#pwm-cells = < 0x3 >;        /* in zephyr\dts\arm\st\f7\stm32f7.dtsi:514 */
			};

			/* node '/soc/timers@40010000/counter' defined in zephyr\dts\arm\st\f7\stm32f7.dtsi:517 */
			counter {
				compatible = "st,stm32-counter"; /* in zephyr\dts\arm\st\f7\stm32f7.dtsi:518 */
				status = "disabled";             /* in zephyr\dts\arm\st\f7\stm32f7.dtsi:519 */
			};

			/* node '/soc/timers@40010000/qdec' defined in zephyr\dts\arm\st\f7\stm32f7.dtsi:522 */
			qdec {
				compatible = "st,stm32-qdec";    /* in zephyr\dts\arm\st\f7\stm32f7.dtsi:523 */
				st,input-filter-level = < 0x0 >; /* in zephyr\dts\arm\st\f7\stm32f7.dtsi:524 */
				status = "disabled";             /* in zephyr\dts\arm\st\f7\stm32f7.dtsi:525 */
			};
		};

		/* node '/soc/timers@40000000' defined in zephyr\dts\arm\st\f7\stm32f7.dtsi:529 */
		timers2: timers@40000000 {
			compatible = "st,stm32-timers"; /* in zephyr\dts\arm\st\f7\stm32f7.dtsi:530 */
			reg = < 0x40000000 0x400 >;     /* in zephyr\dts\arm\st\f7\stm32f7.dtsi:531 */
			clocks = < &rcc 0x40 0x1 >,
			         < &rcc 0x13 0xff >;    /* in zephyr\dts\arm\st\f7\stm32f7.dtsi:532 */
			resets = < &rctl 0x400 >;       /* in zephyr\dts\arm\st\f7\stm32f7.dtsi:534 */
			interrupts = < 0x1c 0x0 >;      /* in zephyr\dts\arm\st\f7\stm32f7.dtsi:535 */
			interrupt-names = "global";     /* in zephyr\dts\arm\st\f7\stm32f7.dtsi:536 */
			st,prescaler = < 0x0 >;         /* in zephyr\dts\arm\st\f7\stm32f7.dtsi:537 */
			status = "disabled";            /* in zephyr\dts\arm\st\f7\stm32f7.dtsi:538 */

			/* node '/soc/timers@40000000/pwm' defined in zephyr\dts\arm\st\f7\stm32f7.dtsi:540 */
			pwm {
				compatible = "st,stm32-pwm"; /* in zephyr\dts\arm\st\f7\stm32f7.dtsi:541 */
				status = "disabled";         /* in zephyr\dts\arm\st\f7\stm32f7.dtsi:542 */
				#pwm-cells = < 0x3 >;        /* in zephyr\dts\arm\st\f7\stm32f7.dtsi:543 */
			};

			/* node '/soc/timers@40000000/counter' defined in zephyr\dts\arm\st\f7\stm32f7.dtsi:546 */
			counter {
				compatible = "st,stm32-counter"; /* in zephyr\dts\arm\st\f7\stm32f7.dtsi:547 */
				status = "disabled";             /* in zephyr\dts\arm\st\f7\stm32f7.dtsi:548 */
			};

			/* node '/soc/timers@40000000/qdec' defined in zephyr\dts\arm\st\f7\stm32f7.dtsi:551 */
			qdec {
				compatible = "st,stm32-qdec";    /* in zephyr\dts\arm\st\f7\stm32f7.dtsi:552 */
				st,input-filter-level = < 0x0 >; /* in zephyr\dts\arm\st\f7\stm32f7.dtsi:553 */
				status = "disabled";             /* in zephyr\dts\arm\st\f7\stm32f7.dtsi:554 */
			};
		};

		/* node '/soc/timers@40000400' defined in zephyr\dts\arm\st\f7\stm32f7.dtsi:558 */
		timers3: timers@40000400 {
			compatible = "st,stm32-timers"; /* in zephyr\dts\arm\st\f7\stm32f7.dtsi:559 */
			reg = < 0x40000400 0x400 >;     /* in zephyr\dts\arm\st\f7\stm32f7.dtsi:560 */
			clocks = < &rcc 0x40 0x2 >,
			         < &rcc 0x13 0xff >;    /* in zephyr\dts\arm\st\f7\stm32f7.dtsi:561 */
			resets = < &rctl 0x401 >;       /* in zephyr\dts\arm\st\f7\stm32f7.dtsi:563 */
			interrupts = < 0x1d 0x0 >;      /* in zephyr\dts\arm\st\f7\stm32f7.dtsi:564 */
			interrupt-names = "global";     /* in zephyr\dts\arm\st\f7\stm32f7.dtsi:565 */
			st,prescaler = < 0x0 >;         /* in zephyr\dts\arm\st\f7\stm32f7.dtsi:566 */
			status = "disabled";            /* in zephyr\dts\arm\st\f7\stm32f7.dtsi:567 */

			/* node '/soc/timers@40000400/pwm' defined in zephyr\dts\arm\st\f7\stm32f7.dtsi:569 */
			pwm {
				compatible = "st,stm32-pwm"; /* in zephyr\dts\arm\st\f7\stm32f7.dtsi:570 */
				status = "disabled";         /* in zephyr\dts\arm\st\f7\stm32f7.dtsi:571 */
				#pwm-cells = < 0x3 >;        /* in zephyr\dts\arm\st\f7\stm32f7.dtsi:572 */
			};

			/* node '/soc/timers@40000400/counter' defined in zephyr\dts\arm\st\f7\stm32f7.dtsi:575 */
			counter {
				compatible = "st,stm32-counter"; /* in zephyr\dts\arm\st\f7\stm32f7.dtsi:576 */
				status = "disabled";             /* in zephyr\dts\arm\st\f7\stm32f7.dtsi:577 */
			};

			/* node '/soc/timers@40000400/qdec' defined in zephyr\dts\arm\st\f7\stm32f7.dtsi:580 */
			qdec {
				compatible = "st,stm32-qdec";    /* in zephyr\dts\arm\st\f7\stm32f7.dtsi:581 */
				st,input-filter-level = < 0x0 >; /* in zephyr\dts\arm\st\f7\stm32f7.dtsi:582 */
				status = "disabled";             /* in zephyr\dts\arm\st\f7\stm32f7.dtsi:583 */
			};
		};

		/* node '/soc/timers@40000800' defined in zephyr\dts\arm\st\f7\stm32f7.dtsi:587 */
		timers4: timers@40000800 {
			compatible = "st,stm32-timers"; /* in zephyr\dts\arm\st\f7\stm32f7.dtsi:588 */
			reg = < 0x40000800 0x400 >;     /* in zephyr\dts\arm\st\f7\stm32f7.dtsi:589 */
			clocks = < &rcc 0x40 0x4 >,
			         < &rcc 0x13 0xff >;    /* in zephyr\dts\arm\st\f7\stm32f7.dtsi:590 */
			resets = < &rctl 0x402 >;       /* in zephyr\dts\arm\st\f7\stm32f7.dtsi:592 */
			interrupts = < 0x1e 0x0 >;      /* in zephyr\dts\arm\st\f7\stm32f7.dtsi:593 */
			interrupt-names = "global";     /* in zephyr\dts\arm\st\f7\stm32f7.dtsi:594 */
			st,prescaler = < 0x0 >;         /* in zephyr\dts\arm\st\f7\stm32f7.dtsi:595 */
			status = "disabled";            /* in zephyr\dts\arm\st\f7\stm32f7.dtsi:596 */

			/* node '/soc/timers@40000800/pwm' defined in zephyr\dts\arm\st\f7\stm32f7.dtsi:598 */
			pwm {
				compatible = "st,stm32-pwm"; /* in zephyr\dts\arm\st\f7\stm32f7.dtsi:599 */
				status = "disabled";         /* in zephyr\dts\arm\st\f7\stm32f7.dtsi:600 */
				#pwm-cells = < 0x3 >;        /* in zephyr\dts\arm\st\f7\stm32f7.dtsi:601 */
			};

			/* node '/soc/timers@40000800/counter' defined in zephyr\dts\arm\st\f7\stm32f7.dtsi:604 */
			counter {
				compatible = "st,stm32-counter"; /* in zephyr\dts\arm\st\f7\stm32f7.dtsi:605 */
				status = "disabled";             /* in zephyr\dts\arm\st\f7\stm32f7.dtsi:606 */
			};

			/* node '/soc/timers@40000800/qdec' defined in zephyr\dts\arm\st\f7\stm32f7.dtsi:609 */
			qdec {
				compatible = "st,stm32-qdec";    /* in zephyr\dts\arm\st\f7\stm32f7.dtsi:610 */
				st,input-filter-level = < 0x0 >; /* in zephyr\dts\arm\st\f7\stm32f7.dtsi:611 */
				status = "disabled";             /* in zephyr\dts\arm\st\f7\stm32f7.dtsi:612 */
			};
		};

		/* node '/soc/timers@40000c00' defined in zephyr\dts\arm\st\f7\stm32f7.dtsi:616 */
		timers5: timers@40000c00 {
			compatible = "st,stm32-timers"; /* in zephyr\dts\arm\st\f7\stm32f7.dtsi:617 */
			reg = < 0x40000c00 0x400 >;     /* in zephyr\dts\arm\st\f7\stm32f7.dtsi:618 */
			clocks = < &rcc 0x40 0x8 >,
			         < &rcc 0x13 0xff >;    /* in zephyr\dts\arm\st\f7\stm32f7.dtsi:619 */
			resets = < &rctl 0x403 >;       /* in zephyr\dts\arm\st\f7\stm32f7.dtsi:621 */
			interrupts = < 0x32 0x0 >;      /* in zephyr\dts\arm\st\f7\stm32f7.dtsi:622 */
			interrupt-names = "global";     /* in zephyr\dts\arm\st\f7\stm32f7.dtsi:623 */
			st,prescaler = < 0x0 >;         /* in zephyr\dts\arm\st\f7\stm32f7.dtsi:624 */
			status = "disabled";            /* in zephyr\dts\arm\st\f7\stm32f7.dtsi:625 */

			/* node '/soc/timers@40000c00/pwm' defined in zephyr\dts\arm\st\f7\stm32f7.dtsi:627 */
			pwm {
				compatible = "st,stm32-pwm"; /* in zephyr\dts\arm\st\f7\stm32f7.dtsi:628 */
				status = "disabled";         /* in zephyr\dts\arm\st\f7\stm32f7.dtsi:629 */
				#pwm-cells = < 0x3 >;        /* in zephyr\dts\arm\st\f7\stm32f7.dtsi:630 */
			};

			/* node '/soc/timers@40000c00/counter' defined in zephyr\dts\arm\st\f7\stm32f7.dtsi:633 */
			counter {
				compatible = "st,stm32-counter"; /* in zephyr\dts\arm\st\f7\stm32f7.dtsi:634 */
				status = "disabled";             /* in zephyr\dts\arm\st\f7\stm32f7.dtsi:635 */
			};

			/* node '/soc/timers@40000c00/qdec' defined in zephyr\dts\arm\st\f7\stm32f7.dtsi:638 */
			qdec {
				compatible = "st,stm32-qdec";    /* in zephyr\dts\arm\st\f7\stm32f7.dtsi:639 */
				st,input-filter-level = < 0x0 >; /* in zephyr\dts\arm\st\f7\stm32f7.dtsi:640 */
				status = "disabled";             /* in zephyr\dts\arm\st\f7\stm32f7.dtsi:641 */
			};
		};

		/* node '/soc/timers@40001000' defined in zephyr\dts\arm\st\f7\stm32f7.dtsi:645 */
		timers6: timers@40001000 {
			compatible = "st,stm32-timers"; /* in zephyr\dts\arm\st\f7\stm32f7.dtsi:646 */
			reg = < 0x40001000 0x400 >;     /* in zephyr\dts\arm\st\f7\stm32f7.dtsi:647 */
			clocks = < &rcc 0x40 0x10 >,
			         < &rcc 0x13 0xff >;    /* in zephyr\dts\arm\st\f7\stm32f7.dtsi:648 */
			resets = < &rctl 0x404 >;       /* in zephyr\dts\arm\st\f7\stm32f7.dtsi:650 */
			interrupts = < 0x36 0x0 >;      /* in zephyr\dts\arm\st\f7\stm32f7.dtsi:651 */
			interrupt-names = "global";     /* in zephyr\dts\arm\st\f7\stm32f7.dtsi:652 */
			st,prescaler = < 0x0 >;         /* in zephyr\dts\arm\st\f7\stm32f7.dtsi:653 */
			status = "disabled";            /* in zephyr\dts\arm\st\f7\stm32f7.dtsi:654 */

			/* node '/soc/timers@40001000/counter' defined in zephyr\dts\arm\st\f7\stm32f7.dtsi:656 */
			counter {
				compatible = "st,stm32-counter"; /* in zephyr\dts\arm\st\f7\stm32f7.dtsi:657 */
				status = "disabled";             /* in zephyr\dts\arm\st\f7\stm32f7.dtsi:658 */
			};
		};

		/* node '/soc/timers@40001400' defined in zephyr\dts\arm\st\f7\stm32f7.dtsi:662 */
		timers7: timers@40001400 {
			compatible = "st,stm32-timers"; /* in zephyr\dts\arm\st\f7\stm32f7.dtsi:663 */
			reg = < 0x40001400 0x400 >;     /* in zephyr\dts\arm\st\f7\stm32f7.dtsi:664 */
			clocks = < &rcc 0x40 0x20 >,
			         < &rcc 0x13 0xff >;    /* in zephyr\dts\arm\st\f7\stm32f7.dtsi:665 */
			resets = < &rctl 0x405 >;       /* in zephyr\dts\arm\st\f7\stm32f7.dtsi:667 */
			interrupts = < 0x37 0x0 >;      /* in zephyr\dts\arm\st\f7\stm32f7.dtsi:668 */
			interrupt-names = "global";     /* in zephyr\dts\arm\st\f7\stm32f7.dtsi:669 */
			st,prescaler = < 0x0 >;         /* in zephyr\dts\arm\st\f7\stm32f7.dtsi:670 */
			status = "disabled";            /* in zephyr\dts\arm\st\f7\stm32f7.dtsi:671 */

			/* node '/soc/timers@40001400/counter' defined in zephyr\dts\arm\st\f7\stm32f7.dtsi:673 */
			counter {
				compatible = "st,stm32-counter"; /* in zephyr\dts\arm\st\f7\stm32f7.dtsi:674 */
				status = "disabled";             /* in zephyr\dts\arm\st\f7\stm32f7.dtsi:675 */
			};
		};

		/* node '/soc/timers@40010400' defined in zephyr\dts\arm\st\f7\stm32f7.dtsi:679 */
		timers8: timers@40010400 {
			compatible = "st,stm32-timers"; /* in zephyr\dts\arm\st\f7\stm32f7.dtsi:680 */
			reg = < 0x40010400 0x400 >;     /* in zephyr\dts\arm\st\f7\stm32f7.dtsi:681 */
			clocks = < &rcc 0x44 0x2 >,
			         < &rcc 0x14 0xff >;    /* in zephyr\dts\arm\st\f7\stm32f7.dtsi:682 */
			resets = < &rctl 0x481 >;       /* in zephyr\dts\arm\st\f7\stm32f7.dtsi:684 */
			interrupts = < 0x2b 0x0 >,
			             < 0x2c 0x0 >,
			             < 0x2d 0x0 >,
			             < 0x2e 0x0 >;      /* in zephyr\dts\arm\st\f7\stm32f7.dtsi:685 */
			interrupt-names = "brk",
			                  "up",
			                  "trgcom",
			                  "cc";         /* in zephyr\dts\arm\st\f7\stm32f7.dtsi:686 */
			st,prescaler = < 0x0 >;         /* in zephyr\dts\arm\st\f7\stm32f7.dtsi:687 */
			status = "disabled";            /* in zephyr\dts\arm\st\f7\stm32f7.dtsi:688 */

			/* node '/soc/timers@40010400/pwm' defined in zephyr\dts\arm\st\f7\stm32f7.dtsi:690 */
			pwm {
				compatible = "st,stm32-pwm"; /* in zephyr\dts\arm\st\f7\stm32f7.dtsi:691 */
				status = "disabled";         /* in zephyr\dts\arm\st\f7\stm32f7.dtsi:692 */
				#pwm-cells = < 0x3 >;        /* in zephyr\dts\arm\st\f7\stm32f7.dtsi:693 */
			};

			/* node '/soc/timers@40010400/counter' defined in zephyr\dts\arm\st\f7\stm32f7.dtsi:696 */
			counter {
				compatible = "st,stm32-counter"; /* in zephyr\dts\arm\st\f7\stm32f7.dtsi:697 */
				status = "disabled";             /* in zephyr\dts\arm\st\f7\stm32f7.dtsi:698 */
			};

			/* node '/soc/timers@40010400/qdec' defined in zephyr\dts\arm\st\f7\stm32f7.dtsi:701 */
			qdec {
				compatible = "st,stm32-qdec";    /* in zephyr\dts\arm\st\f7\stm32f7.dtsi:702 */
				st,input-filter-level = < 0x0 >; /* in zephyr\dts\arm\st\f7\stm32f7.dtsi:703 */
				status = "disabled";             /* in zephyr\dts\arm\st\f7\stm32f7.dtsi:704 */
			};
		};

		/* node '/soc/timers@40014000' defined in zephyr\dts\arm\st\f7\stm32f7.dtsi:708 */
		timers9: timers@40014000 {
			compatible = "st,stm32-timers"; /* in zephyr\dts\arm\st\f7\stm32f7.dtsi:709 */
			reg = < 0x40014000 0x400 >;     /* in zephyr\dts\arm\st\f7\stm32f7.dtsi:710 */
			clocks = < &rcc 0x44 0x10000 >,
			         < &rcc 0x14 0xff >;    /* in zephyr\dts\arm\st\f7\stm32f7.dtsi:711 */
			resets = < &rctl 0x490 >;       /* in zephyr\dts\arm\st\f7\stm32f7.dtsi:713 */
			interrupts = < 0x18 0x0 >;      /* in zephyr\dts\arm\st\f7\stm32f7.dtsi:714 */
			interrupt-names = "global";     /* in zephyr\dts\arm\st\f7\stm32f7.dtsi:715 */
			st,prescaler = < 0x0 >;         /* in zephyr\dts\arm\st\f7\stm32f7.dtsi:716 */
			status = "disabled";            /* in zephyr\dts\arm\st\f7\stm32f7.dtsi:717 */

			/* node '/soc/timers@40014000/pwm' defined in zephyr\dts\arm\st\f7\stm32f7.dtsi:719 */
			pwm {
				compatible = "st,stm32-pwm"; /* in zephyr\dts\arm\st\f7\stm32f7.dtsi:720 */
				status = "disabled";         /* in zephyr\dts\arm\st\f7\stm32f7.dtsi:721 */
				#pwm-cells = < 0x3 >;        /* in zephyr\dts\arm\st\f7\stm32f7.dtsi:722 */
			};

			/* node '/soc/timers@40014000/counter' defined in zephyr\dts\arm\st\f7\stm32f7.dtsi:725 */
			counter {
				compatible = "st,stm32-counter"; /* in zephyr\dts\arm\st\f7\stm32f7.dtsi:726 */
				status = "disabled";             /* in zephyr\dts\arm\st\f7\stm32f7.dtsi:727 */
			};
		};

		/* node '/soc/timers@40014400' defined in zephyr\dts\arm\st\f7\stm32f7.dtsi:731 */
		timers10: timers@40014400 {
			compatible = "st,stm32-timers"; /* in zephyr\dts\arm\st\f7\stm32f7.dtsi:732 */
			reg = < 0x40014400 0x400 >;     /* in zephyr\dts\arm\st\f7\stm32f7.dtsi:733 */
			clocks = < &rcc 0x44 0x20000 >,
			         < &rcc 0x14 0xff >;    /* in zephyr\dts\arm\st\f7\stm32f7.dtsi:734 */
			resets = < &rctl 0x491 >;       /* in zephyr\dts\arm\st\f7\stm32f7.dtsi:736 */
			interrupts = < 0x19 0x0 >;      /* in zephyr\dts\arm\st\f7\stm32f7.dtsi:737 */
			interrupt-names = "global";     /* in zephyr\dts\arm\st\f7\stm32f7.dtsi:738 */
			st,prescaler = < 0x0 >;         /* in zephyr\dts\arm\st\f7\stm32f7.dtsi:739 */
			status = "disabled";            /* in zephyr\dts\arm\st\f7\stm32f7.dtsi:740 */

			/* node '/soc/timers@40014400/pwm' defined in zephyr\dts\arm\st\f7\stm32f7.dtsi:742 */
			pwm {
				compatible = "st,stm32-pwm"; /* in zephyr\dts\arm\st\f7\stm32f7.dtsi:743 */
				status = "disabled";         /* in zephyr\dts\arm\st\f7\stm32f7.dtsi:744 */
				#pwm-cells = < 0x3 >;        /* in zephyr\dts\arm\st\f7\stm32f7.dtsi:745 */
			};

			/* node '/soc/timers@40014400/counter' defined in zephyr\dts\arm\st\f7\stm32f7.dtsi:748 */
			counter {
				compatible = "st,stm32-counter"; /* in zephyr\dts\arm\st\f7\stm32f7.dtsi:749 */
				status = "disabled";             /* in zephyr\dts\arm\st\f7\stm32f7.dtsi:750 */
			};
		};

		/* node '/soc/timers@40014800' defined in zephyr\dts\arm\st\f7\stm32f7.dtsi:754 */
		timers11: timers@40014800 {
			compatible = "st,stm32-timers"; /* in zephyr\dts\arm\st\f7\stm32f7.dtsi:755 */
			reg = < 0x40014800 0x400 >;     /* in zephyr\dts\arm\st\f7\stm32f7.dtsi:756 */
			clocks = < &rcc 0x44 0x40000 >,
			         < &rcc 0x14 0xff >;    /* in zephyr\dts\arm\st\f7\stm32f7.dtsi:757 */
			resets = < &rctl 0x492 >;       /* in zephyr\dts\arm\st\f7\stm32f7.dtsi:759 */
			interrupts = < 0x1a 0x0 >;      /* in zephyr\dts\arm\st\f7\stm32f7.dtsi:760 */
			interrupt-names = "global";     /* in zephyr\dts\arm\st\f7\stm32f7.dtsi:761 */
			st,prescaler = < 0x0 >;         /* in zephyr\dts\arm\st\f7\stm32f7.dtsi:762 */
			status = "disabled";            /* in zephyr\dts\arm\st\f7\stm32f7.dtsi:763 */

			/* node '/soc/timers@40014800/pwm' defined in zephyr\dts\arm\st\f7\stm32f7.dtsi:765 */
			pwm {
				compatible = "st,stm32-pwm"; /* in zephyr\dts\arm\st\f7\stm32f7.dtsi:766 */
				status = "disabled";         /* in zephyr\dts\arm\st\f7\stm32f7.dtsi:767 */
				#pwm-cells = < 0x3 >;        /* in zephyr\dts\arm\st\f7\stm32f7.dtsi:768 */
			};

			/* node '/soc/timers@40014800/counter' defined in zephyr\dts\arm\st\f7\stm32f7.dtsi:771 */
			counter {
				compatible = "st,stm32-counter"; /* in zephyr\dts\arm\st\f7\stm32f7.dtsi:772 */
				status = "disabled";             /* in zephyr\dts\arm\st\f7\stm32f7.dtsi:773 */
			};
		};

		/* node '/soc/timers@40001800' defined in zephyr\dts\arm\st\f7\stm32f7.dtsi:777 */
		timers12: timers@40001800 {
			compatible = "st,stm32-timers"; /* in zephyr\dts\arm\st\f7\stm32f7.dtsi:778 */
			reg = < 0x40001800 0x400 >;     /* in zephyr\dts\arm\st\f7\stm32f7.dtsi:779 */
			clocks = < &rcc 0x40 0x40 >,
			         < &rcc 0x13 0xff >;    /* in zephyr\dts\arm\st\f7\stm32f7.dtsi:780 */
			resets = < &rctl 0x406 >;       /* in zephyr\dts\arm\st\f7\stm32f7.dtsi:782 */
			interrupts = < 0x2b 0x0 >;      /* in zephyr\dts\arm\st\f7\stm32f7.dtsi:783 */
			interrupt-names = "global";     /* in zephyr\dts\arm\st\f7\stm32f7.dtsi:784 */
			st,prescaler = < 0x0 >;         /* in zephyr\dts\arm\st\f7\stm32f7.dtsi:785 */
			status = "disabled";            /* in zephyr\dts\arm\st\f7\stm32f7.dtsi:786 */

			/* node '/soc/timers@40001800/pwm' defined in zephyr\dts\arm\st\f7\stm32f7.dtsi:788 */
			pwm {
				compatible = "st,stm32-pwm"; /* in zephyr\dts\arm\st\f7\stm32f7.dtsi:789 */
				status = "disabled";         /* in zephyr\dts\arm\st\f7\stm32f7.dtsi:790 */
				#pwm-cells = < 0x3 >;        /* in zephyr\dts\arm\st\f7\stm32f7.dtsi:791 */
			};

			/* node '/soc/timers@40001800/counter' defined in zephyr\dts\arm\st\f7\stm32f7.dtsi:794 */
			counter {
				compatible = "st,stm32-counter"; /* in zephyr\dts\arm\st\f7\stm32f7.dtsi:795 */
				status = "disabled";             /* in zephyr\dts\arm\st\f7\stm32f7.dtsi:796 */
			};
		};

		/* node '/soc/timers@40001c00' defined in zephyr\dts\arm\st\f7\stm32f7.dtsi:800 */
		timers13: timers@40001c00 {
			compatible = "st,stm32-timers"; /* in zephyr\dts\arm\st\f7\stm32f7.dtsi:801 */
			reg = < 0x40001c00 0x400 >;     /* in zephyr\dts\arm\st\f7\stm32f7.dtsi:802 */
			clocks = < &rcc 0x40 0x80 >,
			         < &rcc 0x13 0xff >;    /* in zephyr\dts\arm\st\f7\stm32f7.dtsi:803 */
			resets = < &rctl 0x407 >;       /* in zephyr\dts\arm\st\f7\stm32f7.dtsi:805 */
			interrupts = < 0x2c 0x0 >;      /* in zephyr\dts\arm\st\f7\stm32f7.dtsi:806 */
			interrupt-names = "global";     /* in zephyr\dts\arm\st\f7\stm32f7.dtsi:807 */
			st,prescaler = < 0x0 >;         /* in zephyr\dts\arm\st\f7\stm32f7.dtsi:808 */
			status = "disabled";            /* in zephyr\dts\arm\st\f7\stm32f7.dtsi:809 */

			/* node '/soc/timers@40001c00/pwm' defined in zephyr\dts\arm\st\f7\stm32f7.dtsi:811 */
			pwm {
				compatible = "st,stm32-pwm"; /* in zephyr\dts\arm\st\f7\stm32f7.dtsi:812 */
				status = "disabled";         /* in zephyr\dts\arm\st\f7\stm32f7.dtsi:813 */
				#pwm-cells = < 0x3 >;        /* in zephyr\dts\arm\st\f7\stm32f7.dtsi:814 */
			};

			/* node '/soc/timers@40001c00/counter' defined in zephyr\dts\arm\st\f7\stm32f7.dtsi:817 */
			counter {
				compatible = "st,stm32-counter"; /* in zephyr\dts\arm\st\f7\stm32f7.dtsi:818 */
				status = "disabled";             /* in zephyr\dts\arm\st\f7\stm32f7.dtsi:819 */
			};
		};

		/* node '/soc/timers@40002000' defined in zephyr\dts\arm\st\f7\stm32f7.dtsi:823 */
		timers14: timers@40002000 {
			compatible = "st,stm32-timers"; /* in zephyr\dts\arm\st\f7\stm32f7.dtsi:824 */
			reg = < 0x40002000 0x400 >;     /* in zephyr\dts\arm\st\f7\stm32f7.dtsi:825 */
			clocks = < &rcc 0x40 0x100 >,
			         < &rcc 0x13 0xff >;    /* in zephyr\dts\arm\st\f7\stm32f7.dtsi:826 */
			resets = < &rctl 0x408 >;       /* in zephyr\dts\arm\st\f7\stm32f7.dtsi:828 */
			interrupts = < 0x2d 0x0 >;      /* in zephyr\dts\arm\st\f7\stm32f7.dtsi:829 */
			interrupt-names = "global";     /* in zephyr\dts\arm\st\f7\stm32f7.dtsi:830 */
			st,prescaler = < 0x0 >;         /* in zephyr\dts\arm\st\f7\stm32f7.dtsi:831 */
			status = "disabled";            /* in zephyr\dts\arm\st\f7\stm32f7.dtsi:832 */

			/* node '/soc/timers@40002000/pwm' defined in zephyr\dts\arm\st\f7\stm32f7.dtsi:834 */
			pwm {
				compatible = "st,stm32-pwm"; /* in zephyr\dts\arm\st\f7\stm32f7.dtsi:835 */
				status = "disabled";         /* in zephyr\dts\arm\st\f7\stm32f7.dtsi:836 */
				#pwm-cells = < 0x3 >;        /* in zephyr\dts\arm\st\f7\stm32f7.dtsi:837 */
			};

			/* node '/soc/timers@40002000/counter' defined in zephyr\dts\arm\st\f7\stm32f7.dtsi:840 */
			counter {
				compatible = "st,stm32-counter"; /* in zephyr\dts\arm\st\f7\stm32f7.dtsi:841 */
				status = "disabled";             /* in zephyr\dts\arm\st\f7\stm32f7.dtsi:842 */
			};
		};

		/* node '/soc/usb@50000000' defined in zephyr\dts\arm\st\f7\stm32f7.dtsi:846 */
		usbotg_fs: usb@50000000 {
			compatible = "st,stm32-otgfs";  /* in zephyr\dts\arm\st\f7\stm32f7.dtsi:847 */
			reg = < 0x50000000 0x40000 >;   /* in zephyr\dts\arm\st\f7\stm32f7.dtsi:848 */
			interrupts = < 0x43 0x0 >;      /* in zephyr\dts\arm\st\f7\stm32f7.dtsi:849 */
			interrupt-names = "otgfs";      /* in zephyr\dts\arm\st\f7\stm32f7.dtsi:850 */
			num-bidir-endpoints = < 0x6 >;  /* in zephyr\dts\arm\st\f7\stm32f7.dtsi:851 */
			ram-size = < 0x500 >;           /* in zephyr\dts\arm\st\f7\stm32f7.dtsi:852 */
			maximum-speed = "full-speed";   /* in zephyr\dts\arm\st\f7\stm32f7.dtsi:853 */
			phys = < &otgfs_phy >;          /* in zephyr\dts\arm\st\f7\stm32f7.dtsi:854 */
			clocks = < &rcc 0x34 0x80 >,
			         < &rcc 0x7 0x1b0090 >; /* in zephyr\dts\arm\st\f7\stm32f7.dtsi:855 */
			status = "disabled";            /* in zephyr\dts\arm\st\f7\stm32f7.dtsi:857 */
		};

		/* node '/soc/usb@40040000' defined in zephyr\dts\arm\st\f7\stm32f7.dtsi:860 */
		usbotg_hs: usb@40040000 {
			compatible = "st,stm32-otghs";     /* in zephyr\dts\arm\st\f7\stm32f7.dtsi:861 */
			reg = < 0x40040000 0x40000 >;      /* in zephyr\dts\arm\st\f7\stm32f7.dtsi:862 */
			interrupts = < 0x4d 0x0 >,
			             < 0x4a 0x0 >,
			             < 0x4b 0x0 >;         /* in zephyr\dts\arm\st\f7\stm32f7.dtsi:863 */
			interrupt-names = "otghs",
			                  "ep1_out",
			                  "ep1_in";        /* in zephyr\dts\arm\st\f7\stm32f7.dtsi:864 */
			num-bidir-endpoints = < 0x9 >;     /* in zephyr\dts\arm\st\f7\stm32f7.dtsi:865 */
			ram-size = < 0x1000 >;             /* in zephyr\dts\arm\st\f7\stm32f7.dtsi:866 */
			maximum-speed = "full-speed";      /* in zephyr\dts\arm\st\f7\stm32f7.dtsi:867 */
			clocks = < &rcc 0x30 0x20000000 >,
			         < &rcc 0x7 0x1b0090 >;    /* in zephyr\dts\arm\st\f7\stm32f7.dtsi:868 */
			phys = < &otghs_fs_phy >;          /* in zephyr\dts\arm\st\f7\stm32f7.dtsi:870 */
			status = "disabled";               /* in zephyr\dts\arm\st\f7\stm32f7.dtsi:871 */
		};

		/* node '/soc/rtc@40002800' defined in zephyr\dts\arm\st\f7\stm32f7.dtsi:874 */
		rtc: rtc@40002800 {
			compatible = "st,stm32-rtc";       /* in zephyr\dts\arm\st\f7\stm32f7.dtsi:875 */
			reg = < 0x40002800 0x300 >;        /* in zephyr\dts\arm\st\f7\stm32f7.dtsi:876 */
			interrupts = < 0x29 0x0 >;         /* in zephyr\dts\arm\st\f7\stm32f7.dtsi:877 */
			clocks = < &rcc 0x40 0x10000000 >; /* in zephyr\dts\arm\st\f7\stm32f7.dtsi:878 */
			prescaler = < 0x8000 >;            /* in zephyr\dts\arm\st\f7\stm32f7.dtsi:879 */
			alarms-count = < 0x2 >;            /* in zephyr\dts\arm\st\f7\stm32f7.dtsi:880 */
			alrm-exti-line = < 0x11 >;         /* in zephyr\dts\arm\st\f7\stm32f7.dtsi:881 */
			status = "disabled";               /* in zephyr\dts\arm\st\f7\stm32f7.dtsi:882 */

			/* node '/soc/rtc@40002800/backup_regs' defined in zephyr\dts\arm\st\f7\stm32f7.dtsi:884 */
			bbram: backup_regs {
				compatible = "st,stm32-bbram"; /* in zephyr\dts\arm\st\f7\stm32f7.dtsi:885 */
				st,backup-regs = < 0x20 >;     /* in zephyr\dts\arm\st\f7\stm32f7.dtsi:886 */
				status = "disabled";           /* in zephyr\dts\arm\st\f7\stm32f7.dtsi:887 */
			};
		};

		/* node '/soc/adc@40012000' defined in zephyr\dts\arm\st\f7\stm32f7.dtsi:891 */
		adc123_common: adc@40012000 {
			compatible = "st,stm32f4-adc",
			             "st,stm32-adc";                                 /* in zephyr\dts\arm\st\f7\stm32f7.dtsi:892 */
			#address-cells = < 0x1 >;                                    /* in zephyr\dts\arm\st\f7\stm32f7.dtsi:893 */
			#size-cells = < 0x1 >;                                       /* in zephyr\dts\arm\st\f7\stm32f7.dtsi:894 */
			reg = < 0x40012000 0x50 >;                                   /* in zephyr\dts\arm\st\f7\stm32f7.dtsi:895 */
			ranges;                                                      /* in zephyr\dts\arm\st\f7\stm32f7.dtsi:896 */
			st,adc-clock-source = "SYNC";                                /* in zephyr\dts\arm\st\f7\stm32f7.dtsi:897 */
			st,adc-resolutions = < 0xc 0xa 0x8 0x6 >;                    /* in zephyr\dts\arm\st\f7\stm32f7.dtsi:898 */
			sampling-times = < 0x3 0xf 0x1c 0x38 0x54 0x70 0x90 0x1e0 >; /* in zephyr\dts\arm\st\f7\stm32f7.dtsi:899 */
			st,adc-sequencer = "programmable";                           /* in zephyr\dts\arm\st\f7\stm32f7.dtsi:900 */
			st,adc-oversampler = "none";                                 /* in zephyr\dts\arm\st\f7\stm32f7.dtsi:901 */
			st,adc-internal-regulator = "none";                          /* in zephyr\dts\arm\st\f7\stm32f7.dtsi:902 */
			st,adc-has-injected-support;                                 /* in zephyr\dts\arm\st\f7\stm32f7.dtsi:903 */
			status = "disabled";                                         /* in zephyr\dts\arm\st\f7\stm32f7.dtsi:904 */

			/* node '/soc/adc@40012000/adc@40012000' defined in zephyr\dts\arm\st\f7\stm32f7.dtsi:906 */
			adc1: adc@40012000 {
				reg = < 0x40012000 0x50 >;    /* in zephyr\dts\arm\st\f7\stm32f7.dtsi:907 */
				clocks = < &rcc 0x44 0x100 >; /* in zephyr\dts\arm\st\f7\stm32f7.dtsi:908 */
				clock-names = "adcx";         /* in zephyr\dts\arm\st\f7\stm32f7.dtsi:909 */
				interrupts = < 0x12 0x0 >;    /* in zephyr\dts\arm\st\f7\stm32f7.dtsi:910 */
				#io-channel-cells = < 0x1 >;  /* in zephyr\dts\arm\st\f7\stm32f7.dtsi:911 */
				status = "disabled";          /* in zephyr\dts\arm\st\f7\stm32f7.dtsi:912 */
				phandle = < 0xa >;            /* in zephyr\dts\arm\st\f7\stm32f7.dtsi:1014 */
			};

			/* node '/soc/adc@40012000/adc@40012100' defined in zephyr\dts\arm\st\f7\stm32f7.dtsi:915 */
			adc2: adc@40012100 {
				reg = < 0x40012100 0x50 >;    /* in zephyr\dts\arm\st\f7\stm32f7.dtsi:916 */
				clocks = < &rcc 0x44 0x200 >; /* in zephyr\dts\arm\st\f7\stm32f7.dtsi:917 */
				clock-names = "adcx";         /* in zephyr\dts\arm\st\f7\stm32f7.dtsi:918 */
				interrupts = < 0x12 0x0 >;    /* in zephyr\dts\arm\st\f7\stm32f7.dtsi:919 */
				#io-channel-cells = < 0x1 >;  /* in zephyr\dts\arm\st\f7\stm32f7.dtsi:920 */
				status = "disabled";          /* in zephyr\dts\arm\st\f7\stm32f7.dtsi:921 */
			};

			/* node '/soc/adc@40012000/adc@40012200' defined in zephyr\dts\arm\st\f7\stm32f7.dtsi:924 */
			adc3: adc@40012200 {
				reg = < 0x40012200 0x50 >;    /* in zephyr\dts\arm\st\f7\stm32f7.dtsi:925 */
				clocks = < &rcc 0x44 0x400 >; /* in zephyr\dts\arm\st\f7\stm32f7.dtsi:926 */
				clock-names = "adcx";         /* in zephyr\dts\arm\st\f7\stm32f7.dtsi:927 */
				interrupts = < 0x12 0x0 >;    /* in zephyr\dts\arm\st\f7\stm32f7.dtsi:928 */
				#io-channel-cells = < 0x1 >;  /* in zephyr\dts\arm\st\f7\stm32f7.dtsi:929 */
				status = "disabled";          /* in zephyr\dts\arm\st\f7\stm32f7.dtsi:930 */
			};
		};

		/* node '/soc/dac@40007400' defined in zephyr\dts\arm\st\f7\stm32f7.dtsi:934 */
		dac1: dac@40007400 {
			compatible = "st,stm32-dac";       /* in zephyr\dts\arm\st\f7\stm32f7.dtsi:935 */
			reg = < 0x40007400 0x400 >;        /* in zephyr\dts\arm\st\f7\stm32f7.dtsi:936 */
			clocks = < &rcc 0x40 0x20000000 >; /* in zephyr\dts\arm\st\f7\stm32f7.dtsi:937 */
			status = "disabled";               /* in zephyr\dts\arm\st\f7\stm32f7.dtsi:938 */
			#io-channel-cells = < 0x1 >;       /* in zephyr\dts\arm\st\f7\stm32f7.dtsi:939 */
		};

		/* node '/soc/dma@40026000' defined in zephyr\dts\arm\st\f7\stm32f7.dtsi:942 */
		dma1: dma@40026000 {
			compatible = "st,stm32-dma-v1";  /* in zephyr\dts\arm\st\f7\stm32f7.dtsi:943 */
			#dma-cells = < 0x4 >;            /* in zephyr\dts\arm\st\f7\stm32f7.dtsi:944 */
			reg = < 0x40026000 0x400 >;      /* in zephyr\dts\arm\st\f7\stm32f7.dtsi:945 */
			interrupts = < 0xb 0x0 >,
			             < 0xc 0x0 >,
			             < 0xd 0x0 >,
			             < 0xe 0x0 >,
			             < 0xf 0x0 >,
			             < 0x10 0x0 >,
			             < 0x11 0x0 >,
			             < 0x2f 0x0 >;       /* in zephyr\dts\arm\st\f7\stm32f7.dtsi:946 */
			clocks = < &rcc 0x30 0x200000 >; /* in zephyr\dts\arm\st\f7\stm32f7.dtsi:947 */
			status = "disabled";             /* in zephyr\dts\arm\st\f7\stm32f7.dtsi:948 */
		};

		/* node '/soc/dma@40026400' defined in zephyr\dts\arm\st\f7\stm32f7.dtsi:951 */
		dma2: dma@40026400 {
			compatible = "st,stm32-dma-v1";  /* in zephyr\dts\arm\st\f7\stm32f7.dtsi:952 */
			#dma-cells = < 0x4 >;            /* in zephyr\dts\arm\st\f7\stm32f7.dtsi:953 */
			reg = < 0x40026400 0x400 >;      /* in zephyr\dts\arm\st\f7\stm32f7.dtsi:954 */
			interrupts = < 0x38 0x0 >,
			             < 0x39 0x0 >,
			             < 0x3a 0x0 >,
			             < 0x3b 0x0 >,
			             < 0x3c 0x0 >,
			             < 0x44 0x0 >,
			             < 0x45 0x0 >,
			             < 0x46 0x0 >;       /* in zephyr\dts\arm\st\f7\stm32f7.dtsi:955 */
			clocks = < &rcc 0x30 0x400000 >; /* in zephyr\dts\arm\st\f7\stm32f7.dtsi:956 */
			st,mem2mem;                      /* in zephyr\dts\arm\st\f7\stm32f7.dtsi:957 */
			status = "disabled";             /* in zephyr\dts\arm\st\f7\stm32f7.dtsi:958 */
			phandle = < 0xe >;               /* in zephyr\dts\arm\st\f7\stm32f7.dtsi:1079 */
		};

		/* node '/soc/rng@50060800' defined in zephyr\dts\arm\st\f7\stm32f7.dtsi:961 */
		rng: rng@50060800 {
			compatible = "st,stm32-rng";    /* in zephyr\dts\arm\st\f7\stm32f7.dtsi:962 */
			reg = < 0x50060800 0x400 >;     /* in zephyr\dts\arm\st\f7\stm32f7.dtsi:963 */
			interrupts = < 0x50 0x0 >;      /* in zephyr\dts\arm\st\f7\stm32f7.dtsi:964 */
			clocks = < &rcc 0x34 0x40 >,
			         < &rcc 0x7 0x1b0090 >; /* in zephyr\dts\arm\st\f7\stm32f7.dtsi:965 */
			status = "disabled";            /* in zephyr\dts\arm\st\f7\stm32f7.dtsi:967 */
		};

		/* node '/soc/sdmmc@40012c00' defined in zephyr\dts\arm\st\f7\stm32f7.dtsi:970 */
		sdmmc1: sdmmc@40012c00 {
			compatible = "st,stm32-sdmmc";  /* in zephyr\dts\arm\st\f7\stm32f7.dtsi:971 */
			reg = < 0x40012c00 0x400 >;     /* in zephyr\dts\arm\st\f7\stm32f7.dtsi:972 */
			clocks = < &rcc 0x44 0x800 >,
			         < &rcc 0x7 0x1c0090 >; /* in zephyr\dts\arm\st\f7\stm32f7.dtsi:973 */
			resets = < &rctl 0x48b >;       /* in zephyr\dts\arm\st\f7\stm32f7.dtsi:975 */
			interrupts = < 0x31 0x0 >;      /* in zephyr\dts\arm\st\f7\stm32f7.dtsi:976 */
			status = "disabled";            /* in zephyr\dts\arm\st\f7\stm32f7.dtsi:977 */
		};

		/* node '/soc/memory@40024000' defined in zephyr\dts\arm\st\f7\stm32f7.dtsi:980 */
		backup_sram: memory@40024000 {
			compatible = "zephyr,memory-region",
			             "st,stm32-backup-sram";  /* in zephyr\dts\arm\st\f7\stm32f7.dtsi:981 */
			reg = < 0x40024000 0x1000 >;          /* in zephyr\dts\arm\st\f7\stm32f7.dtsi:982 */
			clocks = < &rcc 0x30 0x40000 >;       /* in zephyr\dts\arm\st\f7\stm32f7.dtsi:983 */
			zephyr,memory-region = "BACKUP_SRAM"; /* in zephyr\dts\arm\st\f7\stm32f7.dtsi:984 */
			status = "disabled";                  /* in zephyr\dts\arm\st\f7\stm32f7.dtsi:985 */
		};

		/* node '/soc/spi@a0001000' defined in zephyr\dts\arm\st\f7\stm32f7.dtsi:988 */
		quadspi: spi@a0001000 {
			compatible = "st,stm32-qspi";    /* in zephyr\dts\arm\st\f7\stm32f7.dtsi:989 */
			#address-cells = < 0x1 >;        /* in zephyr\dts\arm\st\f7\stm32f7.dtsi:990 */
			#size-cells = < 0x0 >;           /* in zephyr\dts\arm\st\f7\stm32f7.dtsi:991 */
			reg = < 0xa0001000 0x1000 >,
			      < 0x90000000 0x10000000 >; /* in zephyr\dts\arm\st\f7\stm32f7.dtsi:992 */
			interrupts = < 0x5c 0x0 >;       /* in zephyr\dts\arm\st\f7\stm32f7.dtsi:993 */
			clocks = < &rcc 0x38 0x2 >;      /* in zephyr\dts\arm\st\f7\stm32f7.dtsi:994 */
			status = "disabled";             /* in zephyr\dts\arm\st\f7\stm32f7.dtsi:995 */
		};

		/* node '/soc/crc@40023000' defined in zephyr\dts\arm\st\f7\stm32f7.dtsi:998 */
		crc: crc@40023000 {
			compatible = "st,stm32-crc";   /* in zephyr\dts\arm\st\f7\stm32f7.dtsi:999 */
			reg = < 0x40023000 0x400 >;    /* in zephyr\dts\arm\st\f7\stm32f7.dtsi:1000 */
			clocks = < &rcc 0x30 0x1000 >; /* in zephyr\dts\arm\st\f7\stm32f7.dtsi:1001 */
			resets = < &rctl 0x20c >;      /* in zephyr\dts\arm\st\f7\stm32f7.dtsi:1002 */
			status = "disabled";           /* in zephyr\dts\arm\st\f7\stm32f7.dtsi:1003 */
		};

		/* node '/soc/i2c@40006000' defined in zephyr\dts\arm\st\f7\stm32f765.dtsi:49 */
		i2c4: i2c@40006000 {
			compatible = "st,stm32-i2c-v2";   /* in zephyr\dts\arm\st\f7\stm32f765.dtsi:50 */
			clock-frequency = < 0x186a0 >;    /* in zephyr\dts\arm\st\f7\stm32f765.dtsi:51 */
			#address-cells = < 0x1 >;         /* in zephyr\dts\arm\st\f7\stm32f765.dtsi:52 */
			#size-cells = < 0x0 >;            /* in zephyr\dts\arm\st\f7\stm32f765.dtsi:53 */
			reg = < 0x40006000 0x400 >;       /* in zephyr\dts\arm\st\f7\stm32f765.dtsi:54 */
			clocks = < &rcc 0x40 0x1000000 >; /* in zephyr\dts\arm\st\f7\stm32f765.dtsi:55 */
			interrupts = < 0x5f 0x0 >,
			             < 0x60 0x0 >;        /* in zephyr\dts\arm\st\f7\stm32f765.dtsi:56 */
			interrupt-names = "event",
			                  "error";        /* in zephyr\dts\arm\st\f7\stm32f765.dtsi:57 */
			status = "disabled";              /* in zephyr\dts\arm\st\f7\stm32f765.dtsi:58 */
			phandle = < 0xf >;                /* in zephyr\dts\arm\st\f7\stm32f765.dtsi:172 */
		};

		/* node '/soc/spi@40015400' defined in zephyr\dts\arm\st\f7\stm32f765.dtsi:61 */
		spi6: spi@40015400 {
			compatible = "st,stm32-spi-fifo",
			             "st,stm32-spi";            /* in zephyr\dts\arm\st\f7\stm32f765.dtsi:62 */
			#address-cells = < 0x1 >;               /* in zephyr\dts\arm\st\f7\stm32f765.dtsi:63 */
			#size-cells = < 0x0 >;                  /* in zephyr\dts\arm\st\f7\stm32f765.dtsi:64 */
			reg = < 0x40015400 0x400 >;             /* in zephyr\dts\arm\st\f7\stm32f765.dtsi:65 */
			clocks = < &rcc 0x44 0x200000 >;        /* in zephyr\dts\arm\st\f7\stm32f765.dtsi:66 */
			interrupts = < 0x56 0x0 >;              /* in zephyr\dts\arm\st\f7\stm32f765.dtsi:67 */
			st,spi-data-width = "full-4-to-16-bit"; /* in zephyr\dts\arm\st\f7\stm32f765.dtsi:68 */
			status = "disabled";                    /* in zephyr\dts\arm\st\f7\stm32f765.dtsi:69 */
		};

		/* node '/soc/dfsdm@40017400' defined in zephyr\dts\arm\st\f7\stm32f765.dtsi:72 */
		dfsdm: dfsdm@40017400 {
			compatible = "st,stm32-dfsdm";     /* in zephyr\dts\arm\st\f7\stm32f765.dtsi:73 */
			reg = < 0x40017400 0x400 >;        /* in zephyr\dts\arm\st\f7\stm32f765.dtsi:74 */
			clocks = < &rcc 0x44 0x20000000 >,
			         < &rcc 0xf 0xff >;        /* in zephyr\dts\arm\st\f7\stm32f765.dtsi:75 */
			clock-names = "pclk",
			              "aclk";              /* in zephyr\dts\arm\st\f7\stm32f765.dtsi:77 */
			resets = < &rctl 0x49d >;          /* in zephyr\dts\arm\st\f7\stm32f765.dtsi:78 */
			#address-cells = < 0x1 >;          /* in zephyr\dts\arm\st\f7\stm32f765.dtsi:79 */
			#size-cells = < 0x0 >;             /* in zephyr\dts\arm\st\f7\stm32f765.dtsi:80 */
			status = "disabled";               /* in zephyr\dts\arm\st\f7\stm32f765.dtsi:81 */

			/* node '/soc/dfsdm@40017400/filter@0' defined in zephyr\dts\arm\st\f7\stm32f765.dtsi:83 */
			pdm0: filter@0 {
				compatible = "st,stm32-dfsdm-dmic"; /* in zephyr\dts\arm\st\f7\stm32f765.dtsi:84 */
				reg = < 0x0 >;                      /* in zephyr\dts\arm\st\f7\stm32f765.dtsi:85 */
				interrupts = < 0x63 0x0 >;          /* in zephyr\dts\arm\st\f7\stm32f765.dtsi:86 */
				filter-order = < 0x5 >;             /* in zephyr\dts\arm\st\f7\stm32f765.dtsi:87 */
				#address-cells = < 0x1 >;           /* in zephyr\dts\arm\st\f7\stm32f765.dtsi:88 */
				#size-cells = < 0x0 >;              /* in zephyr\dts\arm\st\f7\stm32f765.dtsi:89 */
				status = "disabled";                /* in zephyr\dts\arm\st\f7\stm32f765.dtsi:90 */
			};

			/* node '/soc/dfsdm@40017400/filter@1' defined in zephyr\dts\arm\st\f7\stm32f765.dtsi:93 */
			pdm1: filter@1 {
				compatible = "st,stm32-dfsdm-dmic"; /* in zephyr\dts\arm\st\f7\stm32f765.dtsi:94 */
				reg = < 0x1 >;                      /* in zephyr\dts\arm\st\f7\stm32f765.dtsi:95 */
				interrupts = < 0x64 0x0 >;          /* in zephyr\dts\arm\st\f7\stm32f765.dtsi:96 */
				filter-order = < 0x5 >;             /* in zephyr\dts\arm\st\f7\stm32f765.dtsi:97 */
				#address-cells = < 0x1 >;           /* in zephyr\dts\arm\st\f7\stm32f765.dtsi:98 */
				#size-cells = < 0x0 >;              /* in zephyr\dts\arm\st\f7\stm32f765.dtsi:99 */
				status = "disabled";                /* in zephyr\dts\arm\st\f7\stm32f765.dtsi:100 */
			};

			/* node '/soc/dfsdm@40017400/filter@2' defined in zephyr\dts\arm\st\f7\stm32f765.dtsi:103 */
			pdm2: filter@2 {
				compatible = "st,stm32-dfsdm-dmic"; /* in zephyr\dts\arm\st\f7\stm32f765.dtsi:104 */
				reg = < 0x2 >;                      /* in zephyr\dts\arm\st\f7\stm32f765.dtsi:105 */
				interrupts = < 0x65 0x0 >;          /* in zephyr\dts\arm\st\f7\stm32f765.dtsi:106 */
				filter-order = < 0x5 >;             /* in zephyr\dts\arm\st\f7\stm32f765.dtsi:107 */
				#address-cells = < 0x1 >;           /* in zephyr\dts\arm\st\f7\stm32f765.dtsi:108 */
				#size-cells = < 0x0 >;              /* in zephyr\dts\arm\st\f7\stm32f765.dtsi:109 */
				status = "disabled";                /* in zephyr\dts\arm\st\f7\stm32f765.dtsi:110 */
			};

			/* node '/soc/dfsdm@40017400/filter@3' defined in zephyr\dts\arm\st\f7\stm32f765.dtsi:113 */
			pdm3: filter@3 {
				compatible = "st,stm32-dfsdm-dmic"; /* in zephyr\dts\arm\st\f7\stm32f765.dtsi:114 */
				reg = < 0x3 >;                      /* in zephyr\dts\arm\st\f7\stm32f765.dtsi:115 */
				interrupts = < 0x66 0x0 >;          /* in zephyr\dts\arm\st\f7\stm32f765.dtsi:116 */
				filter-order = < 0x5 >;             /* in zephyr\dts\arm\st\f7\stm32f765.dtsi:117 */
				#address-cells = < 0x1 >;           /* in zephyr\dts\arm\st\f7\stm32f765.dtsi:118 */
				#size-cells = < 0x0 >;              /* in zephyr\dts\arm\st\f7\stm32f765.dtsi:119 */
				status = "disabled";                /* in zephyr\dts\arm\st\f7\stm32f765.dtsi:120 */
			};
		};

		/* node '/soc/ethernet@40028000' defined in zephyr\dts\arm\st\f7\stm32f765.dtsi:124 */
		mac: ethernet@40028000 {
			compatible = "st,stm32-ethernet",
			             "snps,dwmac";             /* in zephyr\dts\arm\st\f7\stm32f765.dtsi:125 */
			reg = < 0x40028000 0x8000 >;           /* in zephyr\dts\arm\st\f7\stm32f765.dtsi:126 */
			clock-names = "stm-eth",
			              "mac-clk-tx",
			              "mac-clk-rx",
			              "mac-clk-ptp";           /* in zephyr\dts\arm\st\f7\stm32f765.dtsi:127 */
			clocks = < &rcc 0x30 0x2000000 >,
			         < &rcc 0x30 0x4000000 >,
			         < &rcc 0x30 0x8000000 >,
			         < &rcc 0x30 0x10000000 >;     /* in zephyr\dts\arm\st\f7\stm32f765.dtsi:128 */
			resets = < &rctl 0x219 >;              /* in zephyr\dts\arm\st\f7\stm32f765.dtsi:132 */
			interrupts = < 0x3d 0x0 >;             /* in zephyr\dts\arm\st\f7\stm32f765.dtsi:133 */
			snps,multicast-filter-bins = < 0x40 >; /* in zephyr\dts\arm\st\f7\stm32f765.dtsi:134 */
			snps,perfect-filter-entries = < 0x4 >; /* in zephyr\dts\arm\st\f7\stm32f765.dtsi:135 */
			status = "disabled";                   /* in zephyr\dts\arm\st\f7\stm32f765.dtsi:136 */

			/* node '/soc/ethernet@40028000/mdio' defined in zephyr\dts\arm\st\f7\stm32f765.dtsi:138 */
			mdio: mdio {
				compatible = "snps,dwmac-mdio"; /* in zephyr\dts\arm\st\f7\stm32f765.dtsi:139 */
				#address-cells = < 0x1 >;       /* in zephyr\dts\arm\st\f7\stm32f765.dtsi:140 */
				#size-cells = < 0x0 >;          /* in zephyr\dts\arm\st\f7\stm32f765.dtsi:141 */
				status = "disabled";            /* in zephyr\dts\arm\st\f7\stm32f765.dtsi:142 */
			};

			/* node '/soc/ethernet@40028000/ptp-clock' defined in zephyr\dts\arm\st\f7\stm32f765.dtsi:145 */
			ptp_clock: ptp-clock {
				compatible = "snps,dwmac-ptp-clock"; /* in zephyr\dts\arm\st\f7\stm32f765.dtsi:146 */
			};
		};

		/* node '/soc/sdmmc@40011c00' defined in zephyr\dts\arm\st\f7\stm32f765.dtsi:150 */
		sdmmc2: sdmmc@40011c00 {
			compatible = "st,stm32-sdmmc";  /* in zephyr\dts\arm\st\f7\stm32f765.dtsi:151 */
			reg = < 0x40011c00 0x400 >;     /* in zephyr\dts\arm\st\f7\stm32f765.dtsi:152 */
			clocks = < &rcc 0x44 0x80 >,
			         < &rcc 0x7 0x1d0090 >; /* in zephyr\dts\arm\st\f7\stm32f765.dtsi:153 */
			resets = < &rctl 0x487 >;       /* in zephyr\dts\arm\st\f7\stm32f765.dtsi:155 */
			interrupts = < 0x67 0x0 >;      /* in zephyr\dts\arm\st\f7\stm32f765.dtsi:156 */
			status = "disabled";            /* in zephyr\dts\arm\st\f7\stm32f765.dtsi:157 */
		};

		/* node '/soc/dma@4002b000' defined in zephyr\dts\arm\st\f7\stm32f765.dtsi:160 */
		dma2d: dma@4002b000 {
			compatible = "st,stm32-dma2d"; /* in zephyr\dts\arm\st\f7\stm32f765.dtsi:161 */
			reg = < 0x4002b000 0xc00 >;    /* in zephyr\dts\arm\st\f7\stm32f765.dtsi:162 */
			interrupts = < 0x5a 0x0 >;     /* in zephyr\dts\arm\st\f7\stm32f765.dtsi:163 */
			status = "disabled";           /* in zephyr\dts\arm\st\f7\stm32f765.dtsi:164 */
		};

		/* node '/soc/display-controller@40016800' defined in zephyr\dts\arm\st\f7\stm32f767.dtsi:15 */
		ltdc: display-controller@40016800 {
			compatible = "st,stm32-ltdc";     /* in zephyr\dts\arm\st\f7\stm32f767.dtsi:16 */
			reg = < 0x40016800 0x200 >;       /* in zephyr\dts\arm\st\f7\stm32f767.dtsi:17 */
			interrupts = < 0x58 0x0 >,
			             < 0x59 0x0 >;        /* in zephyr\dts\arm\st\f7\stm32f767.dtsi:18 */
			interrupt-names = "ltdc",
			                  "ltdc_err";     /* in zephyr\dts\arm\st\f7\stm32f767.dtsi:19 */
			clocks = < &rcc 0x44 0x4000000 >; /* in zephyr\dts\arm\st\f7\stm32f767.dtsi:20 */
			resets = < &rctl 0x49a >;         /* in zephyr\dts\arm\st\f7\stm32f767.dtsi:21 */
			status = "disabled";              /* in zephyr\dts\arm\st\f7\stm32f767.dtsi:22 */
		};

		/* node '/soc/dsihost@40016c00' defined in zephyr\dts\arm\st\f7\stm32f767.dtsi:25 */
		mipi_dsi: dsihost@40016c00 {
			compatible = "st,stm32-mipi-dsi"; /* in zephyr\dts\arm\st\f7\stm32f767.dtsi:26 */
			#address-cells = < 0x1 >;         /* in zephyr\dts\arm\st\f7\stm32f767.dtsi:27 */
			#size-cells = < 0x0 >;            /* in zephyr\dts\arm\st\f7\stm32f767.dtsi:28 */
			reg = < 0x40016c00 0x800 >;       /* in zephyr\dts\arm\st\f7\stm32f767.dtsi:29 */
			clock-names = "dsiclk",
			              "refclk",
			              "pixelclk";         /* in zephyr\dts\arm\st\f7\stm32f767.dtsi:30 */
			clocks = < &rcc 0x44 0x8000000 >,
			         < &rcc 0x5 0xff >,
			         < &rcc 0x11 0xff >;      /* in zephyr\dts\arm\st\f7\stm32f767.dtsi:31 */
			resets = < &rctl 0x49b >;         /* in zephyr\dts\arm\st\f7\stm32f767.dtsi:34 */
			status = "disabled";              /* in zephyr\dts\arm\st\f7\stm32f767.dtsi:35 */
		};

		/* node '/soc/codec@50051000' defined in zephyr\dts\arm\st\f7\stm32f767.dtsi:38 */
		jpeg: codec@50051000 {
			compatible = "st,stm32-jpeg"; /* in zephyr\dts\arm\st\f7\stm32f767.dtsi:39 */
			reg = < 0x50051000 0x1000 >;  /* in zephyr\dts\arm\st\f7\stm32f767.dtsi:40 */
			interrupts = < 0x6c 0x0 >;    /* in zephyr\dts\arm\st\f7\stm32f767.dtsi:41 */
			clocks = < &rcc 0x34 0x2 >;   /* in zephyr\dts\arm\st\f7\stm32f767.dtsi:42 */
			resets = < &rctl 0x281 >;     /* in zephyr\dts\arm\st\f7\stm32f767.dtsi:43 */
			status = "disabled";          /* in zephyr\dts\arm\st\f7\stm32f767.dtsi:44 */
		};
	};

	/* node '/cpus' defined in zephyr\dts\arm\st\f7\stm32f7.dtsi:33 */
	cpus {
		#address-cells = < 0x1 >; /* in zephyr\dts\arm\st\f7\stm32f7.dtsi:34 */
		#size-cells = < 0x0 >;    /* in zephyr\dts\arm\st\f7\stm32f7.dtsi:35 */

		/* node '/cpus/cpu@0' defined in zephyr\dts\arm\st\f7\stm32f7.dtsi:37 */
		cpu0: cpu@0 {
			device_type = "cpu";          /* in zephyr\dts\arm\st\f7\stm32f7.dtsi:38 */
			compatible = "arm,cortex-m7"; /* in zephyr\dts\arm\st\f7\stm32f7.dtsi:39 */
			reg = < 0x0 >;                /* in zephyr\dts\arm\st\f7\stm32f7.dtsi:40 */
			#address-cells = < 0x1 >;     /* in zephyr\dts\arm\st\f7\stm32f7.dtsi:41 */
			#size-cells = < 0x1 >;        /* in zephyr\dts\arm\st\f7\stm32f7.dtsi:42 */

			/* node '/cpus/cpu@0/mpu@e000ed90' defined in zephyr\dts\arm\st\f7\stm32f7.dtsi:44 */
			mpu: mpu@e000ed90 {
				compatible = "arm,armv7m-mpu"; /* in zephyr\dts\arm\st\f7\stm32f7.dtsi:45 */
				reg = < 0xe000ed90 0x40 >;     /* in zephyr\dts\arm\st\f7\stm32f7.dtsi:46 */
			};
		};
	};

	/* node '/memory-placeholder@90000000' defined in zephyr\dts\arm\st\f7\stm32f7.dtsi:51 */
	quadspi_memory: memory-placeholder@90000000 {
		compatible = "zephyr,memory-region",
		             "mmio-sram";                  /* in zephyr\dts\arm\st\f7\stm32f7.dtsi:52 */
		reg = < 0x90000000 0x10000000 >;           /* in zephyr\dts\arm\st\f7\stm32f7.dtsi:53 */
		zephyr,memory-region = "QSPI_PLACEHOLDER"; /* in zephyr\dts\arm\st\f7\stm32f7.dtsi:54 */
		zephyr,memory-attr = < 0x2000000 >;        /* in zephyr\dts\arm\st\f7\stm32f7.dtsi:55 */
	};

	/* node '/clocks' defined in zephyr\dts\arm\st\f7\stm32f7.dtsi:58 */
	clocks {

		/* node '/clocks/clk-hse' defined in zephyr\dts\arm\st\f7\stm32f7.dtsi:59 */
		clk_hse: clk-hse {
			#clock-cells = < 0x0 >;            /* in zephyr\dts\arm\st\f7\stm32f7.dtsi:60 */
			compatible = "st,stm32-hse-clock"; /* in zephyr\dts\arm\st\f7\stm32f7.dtsi:61 */
			status = "okay";                   /* in MCU_Testbench\boards\arm\MCU_Testbench\MCU_Testbench.dts:29 */
			clock-frequency = < 0x17d7840 >;   /* in MCU_Testbench\boards\arm\MCU_Testbench\MCU_Testbench.dts:30 */
			phandle = < 0x7 >;                 /* in MCU_Testbench\boards\arm\MCU_Testbench\MCU_Testbench.dts:52 */
		};

		/* node '/clocks/clk-hsi' defined in zephyr\dts\arm\st\f7\stm32f7.dtsi:65 */
		clk_hsi: clk-hsi {
			#clock-cells = < 0x0 >;         /* in zephyr\dts\arm\st\f7\stm32f7.dtsi:66 */
			compatible = "fixed-clock";     /* in zephyr\dts\arm\st\f7\stm32f7.dtsi:67 */
			clock-frequency = < 0xf42400 >; /* in zephyr\dts\arm\st\f7\stm32f7.dtsi:68 */
			status = "disabled";            /* in zephyr\dts\arm\st\f7\stm32f7.dtsi:69 */
		};

		/* node '/clocks/clk-lse' defined in zephyr\dts\arm\st\f7\stm32f7.dtsi:72 */
		clk_lse: clk-lse {
			#clock-cells = < 0x0 >;            /* in zephyr\dts\arm\st\f7\stm32f7.dtsi:73 */
			compatible = "st,stm32-lse-clock"; /* in zephyr\dts\arm\st\f7\stm32f7.dtsi:74 */
			clock-frequency = < 0x8000 >;      /* in zephyr\dts\arm\st\f7\stm32f7.dtsi:75 */
			driving-capability = < 0x0 >;      /* in zephyr\dts\arm\st\f7\stm32f7.dtsi:76 */
			status = "disabled";               /* in zephyr\dts\arm\st\f7\stm32f7.dtsi:77 */
		};

		/* node '/clocks/clk-lsi' defined in zephyr\dts\arm\st\f7\stm32f7.dtsi:80 */
		clk_lsi: clk-lsi {
			#clock-cells = < 0x0 >;       /* in zephyr\dts\arm\st\f7\stm32f7.dtsi:81 */
			compatible = "fixed-clock";   /* in zephyr\dts\arm\st\f7\stm32f7.dtsi:82 */
			clock-frequency = < 0x7d00 >; /* in zephyr\dts\arm\st\f7\stm32f7.dtsi:83 */
			status = "disabled";          /* in zephyr\dts\arm\st\f7\stm32f7.dtsi:84 */
		};

		/* node '/clocks/pll' defined in zephyr\dts\arm\st\f7\stm32f7.dtsi:87 */
		pll: pll {
			#clock-cells = < 0x0 >;              /* in zephyr\dts\arm\st\f7\stm32f7.dtsi:88 */
			compatible = "st,stm32fx-pll-clock"; /* in zephyr\dts\arm\st\f7\stm32f7.dtsi:89 */
			div-m = < 0x19 >;                    /* in MCU_Testbench\boards\arm\MCU_Testbench\MCU_Testbench.dts:47 */
			mul-n = < 0x1b0 >;                   /* in MCU_Testbench\boards\arm\MCU_Testbench\MCU_Testbench.dts:48 */
			div-p = < 0x2 >;                     /* in MCU_Testbench\boards\arm\MCU_Testbench\MCU_Testbench.dts:49 */
			div-q = < 0x9 >;                     /* in MCU_Testbench\boards\arm\MCU_Testbench\MCU_Testbench.dts:50 */
			clocks = < &clk_hse >;               /* in MCU_Testbench\boards\arm\MCU_Testbench\MCU_Testbench.dts:52 */
			status = "okay";                     /* in MCU_Testbench\boards\arm\MCU_Testbench\MCU_Testbench.dts:53 */
			phandle = < 0x3 >;                   /* in MCU_Testbench\boards\arm\MCU_Testbench\MCU_Testbench.dts:58 */
		};

		/* node '/clocks/plli2s' defined in zephyr\dts\arm\st\f7\stm32f7.dtsi:93 */
		plli2s: plli2s {
			#clock-cells = < 0x0 >;              /* in zephyr\dts\arm\st\f7\stm32f7.dtsi:94 */
			compatible = "st,stm32fx-pll-clock"; /* in zephyr\dts\arm\st\f7\stm32f7.dtsi:95 */
			status = "disabled";                 /* in zephyr\dts\arm\st\f7\stm32f7.dtsi:96 */
		};

		/* node '/clocks/pllsai' defined in zephyr\dts\arm\st\f7\stm32f7.dtsi:99 */
		pllsai: pllsai {
			compatible = "st,stm32fx-pll-clock"; /* in zephyr\dts\arm\st\f7\stm32f7.dtsi:100 */
			#clock-cells = < 0x0 >;              /* in zephyr\dts\arm\st\f7\stm32f7.dtsi:101 */
			status = "disabled";                 /* in zephyr\dts\arm\st\f7\stm32f7.dtsi:102 */
		};

		/* node '/clocks/clk48' defined in zephyr\dts\arm\st\f7\stm32f7.dtsi:105 */
		clk48: clk48 {
			#clock-cells = < 0x0 >;            /* in zephyr\dts\arm\st\f7\stm32f7.dtsi:106 */
			compatible = "st,stm32-clock-mux"; /* in zephyr\dts\arm\st\f7\stm32f7.dtsi:107 */
			clocks = < &rcc 0x7 0x1b0090 >;    /* in zephyr\dts\arm\st\f7\stm32f7.dtsi:108 */
			status = "disabled";               /* in zephyr\dts\arm\st\f7\stm32f7.dtsi:109 */
		};
	};

	/* node '/mcos' defined in zephyr\dts\arm\st\f7\stm32f7.dtsi:113 */
	mcos {

		/* node '/mcos/mco1' defined in zephyr\dts\arm\st\f7\stm32f7.dtsi:114 */
		mco1: mco1 {
			compatible = "st,stm32-clock-mco"; /* in zephyr\dts\arm\st\f7\stm32f7.dtsi:115 */
			clock-names = "clksel";            /* in zephyr\dts\arm\st\f7\stm32f7.dtsi:116 */
			status = "disabled";               /* in zephyr\dts\arm\st\f7\stm32f7.dtsi:117 */
		};

		/* node '/mcos/mco2' defined in zephyr\dts\arm\st\f7\stm32f7.dtsi:120 */
		mco2: mco2 {
			compatible = "st,stm32-clock-mco"; /* in zephyr\dts\arm\st\f7\stm32f7.dtsi:121 */
			clock-names = "clksel";            /* in zephyr\dts\arm\st\f7\stm32f7.dtsi:122 */
			status = "disabled";               /* in zephyr\dts\arm\st\f7\stm32f7.dtsi:123 */
		};
	};

	/* node '/dietemp' defined in zephyr\dts\arm\st\f7\stm32f7.dtsi:1007 */
	die_temp: dietemp {
		compatible = "st,stm32-temp-cal"; /* in zephyr\dts\arm\st\f7\stm32f7.dtsi:1008 */
		nvmem-cells = < &ts_cal1_otp >,
		              < &ts_cal2_otp >;   /* in zephyr\dts\arm\st\f7\stm32f7.dtsi:1009 */
		nvmem-cell-names = "TS_CAL1",
		                   "TS_CAL2";     /* in zephyr\dts\arm\st\f7\stm32f7.dtsi:1010 */
		ts-cal1-temp = < 0x1e >;          /* in zephyr\dts\arm\st\f7\stm32f7.dtsi:1011 */
		ts-cal2-temp = < 0x6e >;          /* in zephyr\dts\arm\st\f7\stm32f7.dtsi:1012 */
		ts-cal-vrefanalog = < 0xce4 >;    /* in zephyr\dts\arm\st\f7\stm32f7.dtsi:1013 */
		io-channels = < &adc1 0x12 >;     /* in zephyr\dts\arm\st\f7\stm32f7.dtsi:1014 */
		status = "disabled";              /* in zephyr\dts\arm\st\f7\stm32f7.dtsi:1015 */
	};

	/* node '/vref' defined in zephyr\dts\arm\st\f7\stm32f7.dtsi:1018 */
	vref: vref {
		compatible = "st,stm32-vref";   /* in zephyr\dts\arm\st\f7\stm32f7.dtsi:1019 */
		nvmem-cells = < &vrefint_otp >; /* in zephyr\dts\arm\st\f7\stm32f7.dtsi:1020 */
		vrefint-cal-mv = < 0xce4 >;     /* in zephyr\dts\arm\st\f7\stm32f7.dtsi:1021 */
		io-channels = < &adc1 0x11 >;   /* in zephyr\dts\arm\st\f7\stm32f7.dtsi:1022 */
		status = "disabled";            /* in zephyr\dts\arm\st\f7\stm32f7.dtsi:1023 */
	};

	/* node '/vbat' defined in zephyr\dts\arm\st\f7\stm32f7.dtsi:1026 */
	vbat: vbat {
		compatible = "st,stm32-vbat"; /* in zephyr\dts\arm\st\f7\stm32f7.dtsi:1027 */
		ratio = < 0x4 >;              /* in zephyr\dts\arm\st\f7\stm32f7.dtsi:1028 */
		io-channels = < &adc1 0x12 >; /* in zephyr\dts\arm\st\f7\stm32f7.dtsi:1029 */
		status = "disabled";          /* in zephyr\dts\arm\st\f7\stm32f7.dtsi:1030 */
	};

	/* node '/otghs_fs_phy' defined in zephyr\dts\arm\st\f7\stm32f7.dtsi:1033 */
	otghs_fs_phy: otghs_fs_phy {
		compatible = "usb-nop-xceiv"; /* in zephyr\dts\arm\st\f7\stm32f7.dtsi:1034 */
		#phy-cells = < 0x0 >;         /* in zephyr\dts\arm\st\f7\stm32f7.dtsi:1035 */
		phandle = < 0x6 >;            /* in zephyr\dts\arm\st\f7\stm32f7.dtsi:870 */
	};

	/* node '/otgfs_phy' defined in zephyr\dts\arm\st\f7\stm32f7.dtsi:1038 */
	otgfs_phy: otgfs_phy {
		compatible = "usb-nop-xceiv"; /* in zephyr\dts\arm\st\f7\stm32f7.dtsi:1039 */
		#phy-cells = < 0x0 >;         /* in zephyr\dts\arm\st\f7\stm32f7.dtsi:1040 */
		phandle = < 0x5 >;            /* in zephyr\dts\arm\st\f7\stm32f7.dtsi:854 */
	};

	/* node '/smbus1' defined in zephyr\dts\arm\st\f7\stm32f7.dtsi:1043 */
	smbus1: smbus1 {
		compatible = "st,stm32-smbus"; /* in zephyr\dts\arm\st\f7\stm32f7.dtsi:1044 */
		#address-cells = < 0x1 >;      /* in zephyr\dts\arm\st\f7\stm32f7.dtsi:1045 */
		#size-cells = < 0x0 >;         /* in zephyr\dts\arm\st\f7\stm32f7.dtsi:1046 */
		i2c = < &i2c2 >;               /* in zephyr\dts\arm\st\f7\stm32f7.dtsi:1047 */
		status = "disabled";           /* in zephyr\dts\arm\st\f7\stm32f7.dtsi:1048 */
	};

	/* node '/smbus2' defined in zephyr\dts\arm\st\f7\stm32f7.dtsi:1051 */
	smbus2: smbus2 {
		compatible = "st,stm32-smbus"; /* in zephyr\dts\arm\st\f7\stm32f7.dtsi:1052 */
		#address-cells = < 0x1 >;      /* in zephyr\dts\arm\st\f7\stm32f7.dtsi:1053 */
		#size-cells = < 0x0 >;         /* in zephyr\dts\arm\st\f7\stm32f7.dtsi:1054 */
		i2c = < &i2c2 >;               /* in zephyr\dts\arm\st\f7\stm32f7.dtsi:1055 */
		status = "disabled";           /* in zephyr\dts\arm\st\f7\stm32f7.dtsi:1056 */
	};

	/* node '/smbus3' defined in zephyr\dts\arm\st\f7\stm32f7.dtsi:1059 */
	smbus3: smbus3 {
		compatible = "st,stm32-smbus"; /* in zephyr\dts\arm\st\f7\stm32f7.dtsi:1060 */
		#address-cells = < 0x1 >;      /* in zephyr\dts\arm\st\f7\stm32f7.dtsi:1061 */
		#size-cells = < 0x0 >;         /* in zephyr\dts\arm\st\f7\stm32f7.dtsi:1062 */
		i2c = < &i2c3 >;               /* in zephyr\dts\arm\st\f7\stm32f7.dtsi:1063 */
		status = "disabled";           /* in zephyr\dts\arm\st\f7\stm32f7.dtsi:1064 */
	};

	/* node '/sai1@40015800' defined in zephyr\dts\arm\st\f7\stm32f7.dtsi:1067 */
	sai1: sai1@40015800 {
		compatible = "st,stm32-sai";     /* in zephyr\dts\arm\st\f7\stm32f7.dtsi:1068 */
		#address-cells = < 0x1 >;        /* in zephyr\dts\arm\st\f7\stm32f7.dtsi:1069 */
		#size-cells = < 0x1 >;           /* in zephyr\dts\arm\st\f7\stm32f7.dtsi:1070 */
		reg = < 0x40015800 0x400 >;      /* in zephyr\dts\arm\st\f7\stm32f7.dtsi:1071 */
		ranges;                          /* in zephyr\dts\arm\st\f7\stm32f7.dtsi:1072 */
		clocks = < &rcc 0x44 0x400000 >; /* in zephyr\dts\arm\st\f7\stm32f7.dtsi:1073 */
		clock-names = "sai_ck";          /* in zephyr\dts\arm\st\f7\stm32f7.dtsi:1074 */
		status = "disabled";             /* in zephyr\dts\arm\st\f7\stm32f7.dtsi:1075 */

		/* node '/sai1@40015800/sai1a@40015804' defined in zephyr\dts\arm\st\f7\stm32f7.dtsi:1077 */
		sai1_a: sai1a@40015804 {
			reg = < 0x40015804 0x20 >;            /* in zephyr\dts\arm\st\f7\stm32f7.dtsi:1078 */
			dmas = < &dma2 0x1 0x0 0x22800 0x0 >; /* in zephyr\dts\arm\st\f7\stm32f7.dtsi:1079 */
			#address-cells = < 0x1 >;             /* in zephyr\dts\arm\st\f7\stm32f7.dtsi:1080 */
			#size-cells = < 0x0 >;                /* in zephyr\dts\arm\st\f7\stm32f7.dtsi:1081 */
			status = "disabled";                  /* in zephyr\dts\arm\st\f7\stm32f7.dtsi:1082 */
		};

		/* node '/sai1@40015800/sai1b@40015824' defined in zephyr\dts\arm\st\f7\stm32f7.dtsi:1085 */
		sai1_b: sai1b@40015824 {
			reg = < 0x40015824 0x20 >;            /* in zephyr\dts\arm\st\f7\stm32f7.dtsi:1086 */
			dmas = < &dma2 0x5 0x0 0x22800 0x0 >; /* in zephyr\dts\arm\st\f7\stm32f7.dtsi:1087 */
			#address-cells = < 0x1 >;             /* in zephyr\dts\arm\st\f7\stm32f7.dtsi:1088 */
			#size-cells = < 0x0 >;                /* in zephyr\dts\arm\st\f7\stm32f7.dtsi:1089 */
			status = "disabled";                  /* in zephyr\dts\arm\st\f7\stm32f7.dtsi:1090 */
		};
	};

	/* node '/sai2@40015c00' defined in zephyr\dts\arm\st\f7\stm32f7.dtsi:1094 */
	sai2: sai2@40015c00 {
		compatible = "st,stm32-sai";     /* in zephyr\dts\arm\st\f7\stm32f7.dtsi:1095 */
		#address-cells = < 0x1 >;        /* in zephyr\dts\arm\st\f7\stm32f7.dtsi:1096 */
		#size-cells = < 0x1 >;           /* in zephyr\dts\arm\st\f7\stm32f7.dtsi:1097 */
		reg = < 0x40015c00 0x400 >;      /* in zephyr\dts\arm\st\f7\stm32f7.dtsi:1098 */
		ranges;                          /* in zephyr\dts\arm\st\f7\stm32f7.dtsi:1099 */
		clocks = < &rcc 0x44 0x800000 >; /* in zephyr\dts\arm\st\f7\stm32f7.dtsi:1100 */
		clock-names = "sai_ck";          /* in zephyr\dts\arm\st\f7\stm32f7.dtsi:1101 */
		status = "disabled";             /* in zephyr\dts\arm\st\f7\stm32f7.dtsi:1102 */

		/* node '/sai2@40015c00/sai2a@40015c04' defined in zephyr\dts\arm\st\f7\stm32f7.dtsi:1104 */
		sai2_a: sai2a@40015c04 {
			reg = < 0x40015c04 0x20 >;            /* in zephyr\dts\arm\st\f7\stm32f7.dtsi:1105 */
			dmas = < &dma2 0x4 0x3 0x22800 0x0 >; /* in zephyr\dts\arm\st\f7\stm32f7.dtsi:1106 */
			#address-cells = < 0x1 >;             /* in zephyr\dts\arm\st\f7\stm32f7.dtsi:1107 */
			#size-cells = < 0x0 >;                /* in zephyr\dts\arm\st\f7\stm32f7.dtsi:1108 */
			status = "disabled";                  /* in zephyr\dts\arm\st\f7\stm32f7.dtsi:1109 */
		};

		/* node '/sai2@40015c00/sai2b@40015c24' defined in zephyr\dts\arm\st\f7\stm32f7.dtsi:1112 */
		sai2_b: sai2b@40015c24 {
			reg = < 0x40015c24 0x20 >;            /* in zephyr\dts\arm\st\f7\stm32f7.dtsi:1113 */
			dmas = < &dma2 0x6 0x3 0x22800 0x0 >; /* in zephyr\dts\arm\st\f7\stm32f7.dtsi:1114 */
			#address-cells = < 0x1 >;             /* in zephyr\dts\arm\st\f7\stm32f7.dtsi:1115 */
			#size-cells = < 0x0 >;                /* in zephyr\dts\arm\st\f7\stm32f7.dtsi:1116 */
			status = "disabled";                  /* in zephyr\dts\arm\st\f7\stm32f7.dtsi:1117 */
		};
	};

	/* node '/memory@20020000' defined in zephyr\dts\arm\st\f7\stm32f765.dtsi:14 */
	sram0: memory@20020000 {
		compatible = "zephyr,memory-region",
		             "mmio-sram";            /* in zephyr\dts\arm\st\f7\stm32f765.dtsi:15 */
		reg = < 0x20020000 0x60000 >;        /* in zephyr\dts\arm\st\f7\stm32f765.dtsi:16 */
		zephyr,memory-region = "SRAM0";      /* in zephyr\dts\arm\st\f7\stm32f765.dtsi:17 */
	};

	/* node '/memory@20000000' defined in zephyr\dts\arm\st\f7\stm32f765.dtsi:20 */
	dtcm: memory@20000000 {
		compatible = "zephyr,memory-region",
		             "arm,dtcm";             /* in zephyr\dts\arm\st\f7\stm32f765.dtsi:21 */
		reg = < 0x20000000 0x20000 >;        /* in zephyr\dts\arm\st\f7\stm32f765.dtsi:22 */
		zephyr,memory-region = "DTCM";       /* in zephyr\dts\arm\st\f7\stm32f765.dtsi:23 */
	};

	/* node '/smbus4' defined in zephyr\dts\arm\st\f7\stm32f765.dtsi:168 */
	smbus4: smbus4 {
		compatible = "st,stm32-smbus"; /* in zephyr\dts\arm\st\f7\stm32f765.dtsi:169 */
		#address-cells = < 0x1 >;      /* in zephyr\dts\arm\st\f7\stm32f765.dtsi:170 */
		#size-cells = < 0x0 >;         /* in zephyr\dts\arm\st\f7\stm32f765.dtsi:171 */
		i2c = < &i2c4 >;               /* in zephyr\dts\arm\st\f7\stm32f765.dtsi:172 */
		status = "disabled";           /* in zephyr\dts\arm\st\f7\stm32f765.dtsi:173 */
	};

	/* node '/leds' defined in MCU_Testbench\boards\arm\MCU_Testbench\MCU_Testbench.dts:17 */
	leds {
		compatible = "gpio-leds"; /* in MCU_Testbench\boards\arm\MCU_Testbench\MCU_Testbench.dts:18 */

		/* node '/leds/led_0' defined in MCU_Testbench\boards\arm\MCU_Testbench\MCU_Testbench.dts:19 */
		exLed: led_0 {
			gpios = < &gpiod 0x4 0x0 >; /* in MCU_Testbench\boards\arm\MCU_Testbench\MCU_Testbench.dts:20 */
		};
	};
};
